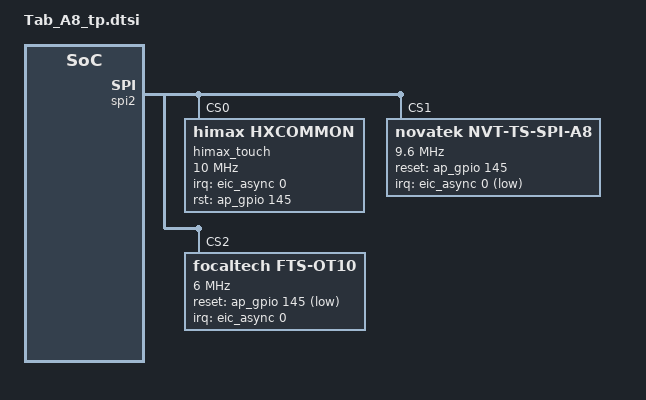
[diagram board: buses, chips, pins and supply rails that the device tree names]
/*Tab A8 code for SR-AX6300-01-23 by fengzhigang at 2021/08/04 start*/
/*Tab A8 code for SR-AX6300-01-373 by luxinjun at 2021/09/17 start*/
&spi2 {
	status = "okay";
	cs-gpios = <0>, <0>, <0>;

	himax_touch@0 {
		compatible = "himax,hxcommon";
		reg = <0>;
		status = "okay";
		spi-max-frequency = <10000000>;
		interrupt-parent = <&ap_gpio>;
		//interrupts = <144 0x2004>;
		himax,panel-sense-nums = <18 32>;
		himax,panel-coords = <0 1200 0 1920>;
		himax,display-coords = <0 1200 0 1920>;
		himax,panel-max-points = <10>;
		himax,int-is-edge = <1>;
		/*Tab A8 code for AX6300DEV-1776 by chenpengbo at 2021/10/28 start*/
		himax,irq-gpio = <&eic_async 0 GPIO_ACTIVE_HIGH>;
		/*Tab A8 code for AX6300DEV-1776 by chenpengbo at 2021/10/28 end*/
		himax,rst-gpio = <&ap_gpio 145 GPIO_ACTIVE_HIGH>;
		report_type = <1>;
	};

	/* Novatek device tree node */
	novatek@1 {
		compatible = "novatek,NVT-ts-spi-a8";
		reg = <1>; //Same as CS ID
		status = "ok";

		spi-max-frequency = <9600000>;	//4800000,9600000,15000000,19200000
		novatek,reset-gpio = <&ap_gpio 145 0x00>;
                /*Tab A8 code for AX6300DEV-1776 by chenpengbo at 2021/10/28 start*/
		novatek,irq-gpio = <&eic_async 0 0x2001>;
                /*Tab A8 code for AX6300DEV-1776 by chenpengbo at 2021/10/28 end*/

		//novatek,pen-support;
		//novatek,stylus-resol-double;

		/* 525 */
		//novatek,swrst-n8-addr = <0x01F01A>;

		/* 672A, 525B, 675, 526, 672C, 523 */
		novatek,swrst-n8-addr = <0x03F0FE>;
		novatek,spi-rd-fast-addr = <0x03F310>;
/*Tab A8 code for SR-AX6300-01-405 by luxinjun at 2021/09/09 start*/
				/*Panel setting*/
		novatek,resolution = <1200 1920>;
		novatek,max_touch_num = <10>;
		novatek,area-size = <56 112 60>;	//indicator navigation edge
		novatek,fw_name = "novatek_ts_fw.bin", "tsp_novatek/nt36525_a01core_tp.bin";
		novatek,fw_name_mp = "novatek_ts_mp.bin", "tsp_novatek/nt36525_a01core_mp.bin";
		//novatek,support_ear_detect_mode;
		novatek,enable_settings_aot;
/*Tab A8 code for SR-AX6300-01-405 by luxinjun at 2021/09/09 end*/
		/* MP */
		novatek,mp-support-dt;

		novatek-mp-criteria-723A@0 {
			#address-cells = <1>;
			#size-cells = <0>;
			compatible = "novatek-mp-criteria-723A";

			/* sec cmd test config */
			open_test_spec = <(-511) 5120>;
			short_test_spec = <10000 14008>;
			diff_test_frame = <50>;
			/* sec cmd fdm test config */
			fdm_x_num = <2>;
			fdm_diff_test_frame = <50>;

			/* MP Config */
			IC_X_CFG_SIZE = <32>;
			IC_Y_CFG_SIZE = <48>;
			IC_KEY_CFG_SIZE = <4>;
			X_Channel = <32>;
			Y_Channel = <48>;
			AIN_X = <0 1 2 3 4 5 6 7 8 9 10 11 12 13 14 15 16 17 18 19 20 21 22 23 24 25 26 27 28 29 30 31>;
			AIN_Y = <0 1 2 3 4 5 6 7 8 9 10 11 12 13 14 15 16 17
						18 19 20 21 22 23 24 25 26 27 28 29 30 31 32 33 34 35 36 37 38 39
						40 41 42 43 44 45 46 47>;
			AIN_KEY = <0 1 2 0xFF 0xFF 0xFF 0xFF 0xFF>;

			/* MP Criteria */
			PS_Config_Lmt_Short_Rawdata_P = <
				14008 14008 14008 14008 14008 14008 14008 14008 14008 14008 14008 14008 14008 14008 14008 14008 14008 14008 14008 14008 14008 14008 14008 14008 14008 14008 14008 14008 14008 14008 14008 14008
				14008 14008 14008 14008 14008 14008 14008 14008 14008 14008 14008 14008 14008 14008 14008 14008 14008 14008 14008 14008 14008 14008 14008 14008 14008 14008 14008 14008 14008 14008 14008 14008
				14008 14008 14008 14008 14008 14008 14008 14008 14008 14008 14008 14008 14008 14008 14008 14008 14008 14008 14008 14008 14008 14008 14008 14008 14008 14008 14008 14008 14008 14008 14008 14008
				14008 14008 14008 14008 14008 14008 14008 14008 14008 14008 14008 14008 14008 14008 14008 14008 14008 14008 14008 14008 14008 14008 14008 14008 14008 14008 14008 14008 14008 14008 14008 14008
				14008 14008 14008 14008 14008 14008 14008 14008 14008 14008 14008 14008 14008 14008 14008 14008 14008 14008 14008 14008 14008 14008 14008 14008 14008 14008 14008 14008 14008 14008 14008 14008
				14008 14008 14008 14008 14008 14008 14008 14008 14008 14008 14008 14008 14008 14008 14008 14008 14008 14008 14008 14008 14008 14008 14008 14008 14008 14008 14008 14008 14008 14008 14008 14008
				14008 14008 14008 14008 14008 14008 14008 14008 14008 14008 14008 14008 14008 14008 14008 14008 14008 14008 14008 14008 14008 14008 14008 14008 14008 14008 14008 14008 14008 14008 14008 14008
				14008 14008 14008 14008 14008 14008 14008 14008 14008 14008 14008 14008 14008 14008 14008 14008 14008 14008 14008 14008 14008 14008 14008 14008 14008 14008 14008 14008 14008 14008 14008 14008
				14008 14008 14008 14008 14008 14008 14008 14008 14008 14008 14008 14008 14008 14008 14008 14008 14008 14008 14008 14008 14008 14008 14008 14008 14008 14008 14008 14008 14008 14008 14008 14008
				14008 14008 14008 14008 14008 14008 14008 14008 14008 14008 14008 14008 14008 14008 14008 14008 14008 14008 14008 14008 14008 14008 14008 14008 14008 14008 14008 14008 14008 14008 14008 14008
				14008 14008 14008 14008 14008 14008 14008 14008 14008 14008 14008 14008 14008 14008 14008 14008 14008 14008 14008 14008 14008 14008 14008 14008 14008 14008 14008 14008 14008 14008 14008 14008
				14008 14008 14008 14008 14008 14008 14008 14008 14008 14008 14008 14008 14008 14008 14008 14008 14008 14008 14008 14008 14008 14008 14008 14008 14008 14008 14008 14008 14008 14008 14008 14008
				14008 14008 14008 14008 14008 14008 14008 14008 14008 14008 14008 14008 14008 14008 14008 14008 14008 14008 14008 14008 14008 14008 14008 14008 14008 14008 14008 14008 14008 14008 14008 14008
				14008 14008 14008 14008 14008 14008 14008 14008 14008 14008 14008 14008 14008 14008 14008 14008 14008 14008 14008 14008 14008 14008 14008 14008 14008 14008 14008 14008 14008 14008 14008 14008
				14008 14008 14008 14008 14008 14008 14008 14008 14008 14008 14008 14008 14008 14008 14008 14008 14008 14008 14008 14008 14008 14008 14008 14008 14008 14008 14008 14008 14008 14008 14008 14008
				14008 14008 14008 14008 14008 14008 14008 14008 14008 14008 14008 14008 14008 14008 14008 14008 14008 14008 14008 14008 14008 14008 14008 14008 14008 14008 14008 14008 14008 14008 14008 14008
				14008 14008 14008 14008 14008 14008 14008 14008 14008 14008 14008 14008 14008 14008 14008 14008 14008 14008 14008 14008 14008 14008 14008 14008 14008 14008 14008 14008 14008 14008 14008 14008
				14008 14008 14008 14008 14008 14008 14008 14008 14008 14008 14008 14008 14008 14008 14008 14008 14008 14008 14008 14008 14008 14008 14008 14008 14008 14008 14008 14008 14008 14008 14008 14008
				14008 14008 14008 14008 14008 14008 14008 14008 14008 14008 14008 14008 14008 14008 14008 14008 14008 14008 14008 14008 14008 14008 14008 14008 14008 14008 14008 14008 14008 14008 14008 14008
				14008 14008 14008 14008 14008 14008 14008 14008 14008 14008 14008 14008 14008 14008 14008 14008 14008 14008 14008 14008 14008 14008 14008 14008 14008 14008 14008 14008 14008 14008 14008 14008
				14008 14008 14008 14008 14008 14008 14008 14008 14008 14008 14008 14008 14008 14008 14008 14008 14008 14008 14008 14008 14008 14008 14008 14008 14008 14008 14008 14008 14008 14008 14008 14008
				14008 14008 14008 14008 14008 14008 14008 14008 14008 14008 14008 14008 14008 14008 14008 14008 14008 14008 14008 14008 14008 14008 14008 14008 14008 14008 14008 14008 14008 14008 14008 14008
				14008 14008 14008 14008 14008 14008 14008 14008 14008 14008 14008 14008 14008 14008 14008 14008 14008 14008 14008 14008 14008 14008 14008 14008 14008 14008 14008 14008 14008 14008 14008 14008
				14008 14008 14008 14008 14008 14008 14008 14008 14008 14008 14008 14008 14008 14008 14008 14008 14008 14008 14008 14008 14008 14008 14008 14008 14008 14008 14008 14008 14008 14008 14008 14008
				14008 14008 14008 14008 14008 14008 14008 14008 14008 14008 14008 14008 14008 14008 14008 14008 14008 14008 14008 14008 14008 14008 14008 14008 14008 14008 14008 14008 14008 14008 14008 14008
				14008 14008 14008 14008 14008 14008 14008 14008 14008 14008 14008 14008 14008 14008 14008 14008 14008 14008 14008 14008 14008 14008 14008 14008 14008 14008 14008 14008 14008 14008 14008 14008
				14008 14008 14008 14008 14008 14008 14008 14008 14008 14008 14008 14008 14008 14008 14008 14008 14008 14008 14008 14008 14008 14008 14008 14008 14008 14008 14008 14008 14008 14008 14008 14008
				14008 14008 14008 14008 14008 14008 14008 14008 14008 14008 14008 14008 14008 14008 14008 14008 14008 14008 14008 14008 14008 14008 14008 14008 14008 14008 14008 14008 14008 14008 14008 14008
				14008 14008 14008 14008 14008 14008 14008 14008 14008 14008 14008 14008 14008 14008 14008 14008 14008 14008 14008 14008 14008 14008 14008 14008 14008 14008 14008 14008 14008 14008 14008 14008
				14008 14008 14008 14008 14008 14008 14008 14008 14008 14008 14008 14008 14008 14008 14008 14008 14008 14008 14008 14008 14008 14008 14008 14008 14008 14008 14008 14008 14008 14008 14008 14008
				14008 14008 14008 14008 14008 14008 14008 14008 14008 14008 14008 14008 14008 14008 14008 14008 14008 14008 14008 14008 14008 14008 14008 14008 14008 14008 14008 14008 14008 14008 14008 14008
				14008 14008 14008 14008 14008 14008 14008 14008 14008 14008 14008 14008 14008 14008 14008 14008 14008 14008 14008 14008 14008 14008 14008 14008 14008 14008 14008 14008 14008 14008 14008 14008
				14008 14008 14008 14008 14008 14008 14008 14008 14008 14008 14008 14008 14008 14008 14008 14008 14008 14008 14008 14008 14008 14008 14008 14008 14008 14008 14008 14008 14008 14008 14008 14008
				14008 14008 14008 14008 14008 14008 14008 14008 14008 14008 14008 14008 14008 14008 14008 14008 14008 14008 14008 14008 14008 14008 14008 14008 14008 14008 14008 14008 14008 14008 14008 14008
				14008 14008 14008 14008 14008 14008 14008 14008 14008 14008 14008 14008 14008 14008 14008 14008 14008 14008 14008 14008 14008 14008 14008 14008 14008 14008 14008 14008 14008 14008 14008 14008
				14008 14008 14008 14008 14008 14008 14008 14008 14008 14008 14008 14008 14008 14008 14008 14008 14008 14008 14008 14008 14008 14008 14008 14008 14008 14008 14008 14008 14008 14008 14008 14008
				14008 14008 14008 14008 14008 14008 14008 14008 14008 14008 14008 14008 14008 14008 14008 14008 14008 14008 14008 14008 14008 14008 14008 14008 14008 14008 14008 14008 14008 14008 14008 14008
				14008 14008 14008 14008 14008 14008 14008 14008 14008 14008 14008 14008 14008 14008 14008 14008 14008 14008 14008 14008 14008 14008 14008 14008 14008 14008 14008 14008 14008 14008 14008 14008
				14008 14008 14008 14008 14008 14008 14008 14008 14008 14008 14008 14008 14008 14008 14008 14008 14008 14008 14008 14008 14008 14008 14008 14008 14008 14008 14008 14008 14008 14008 14008 14008
				14008 14008 14008 14008 14008 14008 14008 14008 14008 14008 14008 14008 14008 14008 14008 14008 14008 14008 14008 14008 14008 14008 14008 14008 14008 14008 14008 14008 14008 14008 14008 14008
				14008 14008 14008 14008 14008 14008 14008 14008 14008 14008 14008 14008 14008 14008 14008 14008 14008 14008 14008 14008 14008 14008 14008 14008 14008 14008 14008 14008 14008 14008 14008 14008
				14008 14008 14008 14008 14008 14008 14008 14008 14008 14008 14008 14008 14008 14008 14008 14008 14008 14008 14008 14008 14008 14008 14008 14008 14008 14008 14008 14008 14008 14008 14008 14008
				14008 14008 14008 14008 14008 14008 14008 14008 14008 14008 14008 14008 14008 14008 14008 14008 14008 14008 14008 14008 14008 14008 14008 14008 14008 14008 14008 14008 14008 14008 14008 14008
				14008 14008 14008 14008 14008 14008 14008 14008 14008 14008 14008 14008 14008 14008 14008 14008 14008 14008 14008 14008 14008 14008 14008 14008 14008 14008 14008 14008 14008 14008 14008 14008
				14008 14008 14008 14008 14008 14008 14008 14008 14008 14008 14008 14008 14008 14008 14008 14008 14008 14008 14008 14008 14008 14008 14008 14008 14008 14008 14008 14008 14008 14008 14008 14008
				14008 14008 14008 14008 14008 14008 14008 14008 14008 14008 14008 14008 14008 14008 14008 14008 14008 14008 14008 14008 14008 14008 14008 14008 14008 14008 14008 14008 14008 14008 14008 14008
				14008 14008 14008 14008 14008 14008 14008 14008 14008 14008 14008 14008 14008 14008 14008 14008 14008 14008 14008 14008 14008 14008 14008 14008 14008 14008 14008 14008 14008 14008 14008 14008
				14008 14008 14008 14008 14008 14008 14008 14008 14008 14008 14008 14008 14008 14008 14008 14008 14008 14008 14008 14008 14008 14008 14008 14008 14008 14008 14008 14008 14008 14008 14008 14008
				14008 14008 14008 14008 14008 14008 14008 14008 14008 14008 14008 14008 14008 14008 14008 14008 14008 14008 14008 14008 14008 14008 14008 14008 14008 14008 14008 14008 14008 14008 14008 14008
				14008 14008 14008 14008 14008 14008 14008 14008 14008 14008 14008 14008 14008 14008 14008 14008 14008 14008 14008 14008 14008 14008 14008 14008 14008 14008 14008 14008 14008 14008 14008 14008
				14008 14008 14008>;

			PS_Config_Lmt_Short_Rawdata_N = <
				10100	10100	10100	10100	10100	10100	10100	10100	10100	10100	10100	10100	10100	10100	10100	10100	10100	10100	10100	10100	10100	10100	10100	10100	10100	10100	10100	10100	10100	10100	10100	10100
				10100	10100	10100	10100	10100	10100	10100	10100	10100	10100	10100	10100	10100	10100	10100	10100	10100	10100	10100	10100	10100	10100	10100	10100	10100	10100	10100	10100	10100	10100	10100	10100
				10100	10100	10100	10100	10100	10100	10100	10100	10100	10100	10100	10100	10100	10100	10100	10100	10100	10100	10100	10100	10100	10100	10100	10100	10100	10100	10100	10100	10100	10100	10100	10100
				10100	10100	10100	10100	10100	10100	10100	10100	10100	10100	10100	10100	10100	10100	10100	10100	10100	10100	10100	10100	10100	10100	10100	10100	10100	10100	10100	10100	10100	10100	10100	10100
				10100	10100	10100	10100	10100	10100	10100	10100	10100	10100	10100	10100	10100	10100	10100	10100	10100	10100	10100	10100	10100	10100	10100	10100	10100	10100	10100	10100	10100	10100	10100	10100
				10100	10100	10100	10100	10100	10100	10100	10100	10100	10100	10100	10100	10100	10100	10100	10100	10100	10100	10100	10100	10100	10100	10100	10100	10100	10100	10100	10100	10100	10100	10100	10100
				10100	10100	10100	10100	10100	10100	10100	10100	10100	10100	10100	10100	10100	10100	10100	10100	10100	10100	10100	10100	10100	10100	10100	10100	10100	10100	10100	10100	10100	10100	10100	10100
				10100	10100	10100	10100	10100	10100	10100	10100	10100	10100	10100	10100	10100	10100	10100	10100	10100	10100	10100	10100	10100	10100	10100	10100	10100	10100	10100	10100	10100	10100	10100	10100
				10100	10100	10100	10100	10100	10100	10100	10100	10100	10100	10100	10100	10100	10100	10100	10100	10100	10100	10100	10100	10100	10100	10100	10100	10100	10100	10100	10100	10100	10100	10100	10100
				10100	10100	10100	10100	10100	10100	10100	10100	10100	10100	10100	10100	10100	10100	10100	10100	10100	10100	10100	10100	10100	10100	10100	10100	10100	10100	10100	10100	10100	10100	10100	10100
				10100	10100	10100	10100	10100	10100	10100	10100	10100	10100	10100	10100	10100	10100	10100	10100	10100	10100	10100	10100	10100	10100	10100	10100	10100	10100	10100	10100	10100	10100	10100	10100
				10100	10100	10100	10100	10100	10100	10100	10100	10100	10100	10100	10100	10100	10100	10100	10100	10100	10100	10100	10100	10100	10100	10100	10100	10100	10100	10100	10100	10100	10100	10100	10100
				10100	10100	10100	10100	10100	10100	10100	10100	10100	10100	10100	10100	10100	10100	10100	10100	10100	10100	10100	10100	10100	10100	10100	10100	10100	10100	10100	10100	10100	10100	10100	10100
				10100	10100	10100	10100	10100	10100	10100	10100	10100	10100	10100	10100	10100	10100	10100	10100	10100	10100	10100	10100	10100	10100	10100	10100	10100	10100	10100	10100	10100	10100	10100	10100
				10100	10100	10100	10100	10100	10100	10100	10100	10100	10100	10100	10100	10100	10100	10100	10100	10100	10100	10100	10100	10100	10100	10100	10100	10100	10100	10100	10100	10100	10100	10100	10100
				10100	10100	10100	10100	10100	10100	10100	10100	10100	10100	10100	10100	10100	10100	10100	10100	10100	10100	10100	10100	10100	10100	10100	10100	10100	10100	10100	10100	10100	10100	10100	10100
				10100	10100	10100	10100	10100	10100	10100	10100	10100	10100	10100	10100	10100	10100	10100	10100	10100	10100	10100	10100	10100	10100	10100	10100	10100	10100	10100	10100	10100	10100	10100	10100
				10100	10100	10100	10100	10100	10100	10100	10100	10100	10100	10100	10100	10100	10100	10100	10100	10100	10100	10100	10100	10100	10100	10100	10100	10100	10100	10100	10100	10100	10100	10100	10100
				10100	10100	10100	10100	10100	10100	10100	10100	10100	10100	10100	10100	10100	10100	10100	10100	10100	10100	10100	10100	10100	10100	10100	10100	10100	10100	10100	10100	10100	10100	10100	10100
				10100	10100	10100	10100	10100	10100	10100	10100	10100	10100	10100	10100	10100	10100	10100	10100	10100	10100	10100	10100	10100	10100	10100	10100	10100	10100	10100	10100	10100	10100	10100	10100
				10100	10100	10100	10100	10100	10100	10100	10100	10100	10100	10100	10100	10100	10100	10100	10100	10100	10100	10100	10100	10100	10100	10100	10100	10100	10100	10100	10100	10100	10100	10100	10100
				10100	10100	10100	10100	10100	10100	10100	10100	10100	10100	10100	10100	10100	10100	10100	10100	10100	10100	10100	10100	10100	10100	10100	10100	10100	10100	10100	10100	10100	10100	10100	10100
				10100	10100	10100	10100	10100	10100	10100	10100	10100	10100	10100	10100	10100	10100	10100	10100	10100	10100	10100	10100	10100	10100	10100	10100	10100	10100	10100	10100	10100	10100	10100	10100
				10100	10100	10100	10100	10100	10100	10100	10100	10100	10100	10100	10100	10100	10100	10100	10100	10100	10100	10100	10100	10100	10100	10100	10100	10100	10100	10100	10100	10100	10100	10100	10100
				10100	10100	10100	10100	10100	10100	10100	10100	10100	10100	10100	10100	10100	10100	10100	10100	10100	10100	10100	10100	10100	10100	10100	10100	10100	10100	10100	10100	10100	10100	10100	10100
				10100	10100	10100	10100	10100	10100	10100	10100	10100	10100	10100	10100	10100	10100	10100	10100	10100	10100	10100	10100	10100	10100	10100	10100	10100	10100	10100	10100	10100	10100	10100	10100
				10100	10100	10100	10100	10100	10100	10100	10100	10100	10100	10100	10100	10100	10100	10100	10100	10100	10100	10100	10100	10100	10100	10100	10100	10100	10100	10100	10100	10100	10100	10100	10100
				10100	10100	10100	10100	10100	10100	10100	10100	10100	10100	10100	10100	10100	10100	10100	10100	10100	10100	10100	10100	10100	10100	10100	10100	10100	10100	10100	10100	10100	10100	10100	10100
				10100	10100	10100	10100	10100	10100	10100	10100	10100	10100	10100	10100	10100	10100	10100	10100	10100	10100	10100	10100	10100	10100	10100	10100	10100	10100	10100	10100	10100	10100	10100	10100
				10100	10100	10100	10100	10100	10100	10100	10100	10100	10100	10100	10100	10100	10100	10100	10100	10100	10100	10100	10100	10100	10100	10100	10100	10100	10100	10100	10100	10100	10100	10100	10100
				10100	10100	10100	10100	10100	10100	10100	10100	10100	10100	10100	10100	10100	10100	10100	10100	10100	10100	10100	10100	10100	10100	10100	10100	10100	10100	10100	10100	10100	10100	10100	10100
				10100	10100	10100	10100	10100	10100	10100	10100	10100	10100	10100	10100	10100	10100	10100	10100	10100	10100	10100	10100	10100	10100	10100	10100	10100	10100	10100	10100	10100	10100	10100	10100
				10100	10100	10100	10100	10100	10100	10100	10100	10100	10100	10100	10100	10100	10100	10100	10100	10100	10100	10100	10100	10100	10100	10100	10100	10100	10100	10100	10100	10100	10100	10100	10100
				10100	10100	10100	10100	10100	10100	10100	10100	10100	10100	10100	10100	10100	10100	10100	10100	10100	10100	10100	10100	10100	10100	10100	10100	10100	10100	10100	10100	10100	10100	10100	10100
				10100	10100	10100	10100	10100	10100	10100	10100	10100	10100	10100	10100	10100	10100	10100	10100	10100	10100	10100	10100	10100	10100	10100	10100	10100	10100	10100	10100	10100	10100	10100	10100
				10100	10100	10100	10100	10100	10100	10100	10100	10100	10100	10100	10100	10100	10100	10100	10100	10100	10100	10100	10100	10100	10100	10100	10100	10100	10100	10100	10100	10100	10100	10100	10100
				10100	10100	10100	10100	10100	10100	10100	10100	10100	10100	10100	10100	10100	10100	10100	10100	10100	10100	10100	10100	10100	10100	10100	10100	10100	10100	10100	10100	10100	10100	10100	10100
				10100	10100	10100	10100	10100	10100	10100	10100	10100	10100	10100	10100	10100	10100	10100	10100	10100	10100	10100	10100	10100	10100	10100	10100	10100	10100	10100	10100	10100	10100	10100	10100
				10100	10100	10100	10100	10100	10100	10100	10100	10100	10100	10100	10100	10100	10100	10100	10100	10100	10100	10100	10100	10100	10100	10100	10100	10100	10100	10100	10100	10100	10100	10100	10100
				10100	10100	10100	10100	10100	10100	10100	10100	10100	10100	10100	10100	10100	10100	10100	10100	10100	10100	10100	10100	10100	10100	10100	10100	10100	10100	10100	10100	10100	10100	10100	10100
				10100	10100	10100	10100	10100	10100	10100	10100	10100	10100	10100	10100	10100	10100	10100	10100	10100	10100	10100	10100	10100	10100	10100	10100	10100	10100	10100	10100	10100	10100	10100	10100
				10100	10100	10100	10100	10100	10100	10100	10100	10100	10100	10100	10100	10100	10100	10100	10100	10100	10100	10100	10100	10100	10100	10100	10100	10100	10100	10100	10100	10100	10100	10100	10100
				10100	10100	10100	10100	10100	10100	10100	10100	10100	10100	10100	10100	10100	10100	10100	10100	10100	10100	10100	10100	10100	10100	10100	10100	10100	10100	10100	10100	10100	10100	10100	10100
				10100	10100	10100	10100	10100	10100	10100	10100	10100	10100	10100	10100	10100	10100	10100	10100	10100	10100	10100	10100	10100	10100	10100	10100	10100	10100	10100	10100	10100	10100	10100	10100
				10100	10100	10100	10100	10100	10100	10100	10100	10100	10100	10100	10100	10100	10100	10100	10100	10100	10100	10100	10100	10100	10100	10100	10100	10100	10100	10100	10100	10100	10100	10100	10100
				10100	10100	10100	10100	10100	10100	10100	10100	10100	10100	10100	10100	10100	10100	10100	10100	10100	10100	10100	10100	10100	10100	10100	10100	10100	10100	10100	10100	10100	10100	10100	10100
				10100	10100	10100	10100	10100	10100	10100	10100	10100	10100	10100	10100	10100	10100	10100	10100	10100	10100	10100	10100	10100	10100	10100	10100	10100	10100	10100	10100	10100	10100	10100	10100
				10100	10100	10100	10100	10100	10100	10100	10100	10100	10100	10100	10100	10100	10100	10100	10100	10100	10100	10100	10100	10100	10100	10100	10100	10100	10100	10100	10100	10100	10100	10100	10100
				10000 10000 10000>;

			PS_Config_Lmt_Open_Rawdata_P = <
				3630	3607	3327	3256	3334	3276	3203	3162	3406	3257	3304	3343	3444	3467	3526	3494	3858	3803	3515	3444	3385	3347	3288	3246	3570	3449	3532	3582	3505	3570	3649	3551
				3743	3630	3346	3264	3313	3242	3224	3169	3381	3239	3318	3362	3427	3493	3490	3467	3887	3789	3525	3452	3375	3318	3281	3242	3542	3451	3536	3606	3540	3592	3586	3605
				3683	3416	3290	3214	3294	3257	3187	3116	3407	3227	3277	3326	3367	3453	3470	3493	3826	3600	3493	3397	3340	3306	3269	3201	3589	3424	3479	3564	3463	3528	3577	3628
				3690	3463	3308	3243	3316	3245	3157	3144	3334	3217	3273	3348	3399	3456	3507	3467	3845	3633	3500	3421	3365	3304	3241	3201	3521	3402	3491	3584	3502	3572	3616	3578
				3721	3423	3365	3182	3259	3220	3171	3103	3320	3213	3262	3313	3371	3402	3466	3448	3868	3586	3547	3388	3305	3266	3234	3185	3483	3442	3467	3526	3460	3502	3553	3568
				3617	3407	3409	3204	3294	3243	3168	3078	3382	3176	3253	3311	3397	3434	3477	3486	3815	3596	3582	3383	3339	3294	3239	3157	3553	3400	3452	3547	3490	3546	3600	3613
				3669	3424	3371	3320	3228	3189	3138	3089	3308	3150	3252	3304	3361	3411	3417	3449	3827	3610	3536	3498	3304	3234	3200	3152	3473	3365	3494	3525	3435	3504	3530	3551
				3638	3367	3362	3357	3249	3221	3162	3094	3358	3189	3214	3295	3351	3435	3459	3458	3785	3574	3550	3533	3294	3269	3227	3159	3512	3403	3451	3501	3453	3535	3579	3600
				3619	3396	3371	3319	3393	3166	3115	3063	3280	3140	3176	3287	3341	3403	3425	3385	3763	3578	3557	3488	3431	3242	3173	3127	3455	3347	3402	3539	3424	3484	3526	3522
				3631	3367	3315	3316	3425	3186	3148	3082	3305	3159	3214	3252	3334	3396	3453	3430	3770	3547	3523	3498	3462	3227	3214	3150	3483	3354	3446	3498	3406	3505	3560	3572
				3572	3357	3347	3329	3379	3315	3092	3029	3266	3110	3171	3220	3337	3400	3420	3407	3740	3518	3526	3509	3418	3353	3179	3088	3420	3330	3392	3459	3452	3486	3512	3526
				3647	3351	3322	3259	3375	3343	3108	3061	3273	3122	3199	3259	3304	3386	3411	3435	3792	3514	3504	3465	3421	3381	3164	3127	3452	3337	3406	3502	3409	3462	3530	3558
				3585	3323	3315	3292	3382	3299	3243	3011	3283	3103	3150	3218	3266	3395	3421	3404	3711	3514	3476	3467	3428	3346	3294	3096	3445	3292	3382	3452	3376	3515	3518	3518
				3640	3374	3306	3269	3323	3304	3259	3031	3232	3122	3168	3248	3306	3368	3416	3395	3780	3540	3469	3445	3395	3354	3316	3085	3441	3326	3400	3470	3425	3477	3507	3536
				3571	3336	3276	3255	3353	3306	3215	3095	3206	3115	3147	3197	3264	3330	3416	3393	3711	3481	3466	3413	3392	3360	3277	3150	3393	3309	3351	3441	3376	3448	3547	3512
				3606	3362	3322	3238	3318	3242	3215	3108	3285	3068	3158	3208	3292	3369	3385	3383	3774	3522	3490	3399	3364	3316	3278	3169	3444	3292	3379	3451	3383	3491	3504	3495
				3560	3304	3285	3207	3302	3271	3215	3067	3214	3040	3147	3186	3241	3325	3351	3393	3698	3465	3431	3395	3332	3312	3284	3134	3368	3266	3357	3399	3353	3442	3476	3544
				3593	3337	3320	3253	3291	3243	3158	3073	3242	3103	3102	3199	3249	3355	3392	3365	3703	3526	3479	3414	3323	3290	3245	3137	3431	3284	3343	3432	3367	3453	3525	3500
				3557	3298	3255	3211	3257	3224	3187	3071	3189	3049	3070	3194	3234	3301	3353	3333	3718	3455	3411	3351	3316	3255	3242	3141	3400	3241	3316	3416	3325	3420	3481	3473
				3530	3325	3285	3243	3301	3211	3158	3017	3228	3063	3148	3150	3248	3308	3389	3369	3662	3463	3477	3393	3334	3249	3217	3102	3381	3284	3344	3397	3355	3431	3493	3521
				3539	3292	3245	3175	3255	3178	3137	3040	3148	3038	3092	3119	3236	3281	3336	3327	3684	3470	3404	3326	3273	3236	3180	3095	3368	3248	3297	3371	3333	3379	3459	3472
				3529	3263	3274	3203	3291	3221	3126	3014	3201	3046	3102	3193	3194	3315	3348	3367	3663	3411	3417	3389	3315	3257	3179	3073	3372	3232	3340	3399	3320	3421	3473	3486
				3522	3277	3236	3161	3224	3182	3096	2997	3159	2994	3078	3140	3168	3306	3330	3318	3637	3434	3417	3316	3253	3204	3169	3043	3368	3210	3305	3351	3294	3402	3434	3458
				3549	3255	3215	3189	3252	3214	3143	2983	3141	3026	3084	3145	3241	3260	3351	3327	3684	3417	3364	3325	3312	3243	3190	3039	3333	3215	3288	3390	3320	3388	3463	3466
				3480	3257	3225	3143	3208	3151	3101	2952	3190	3003	3036	3129	3190	3231	3369	3319	3633	3402	3382	3318	3241	3183	3138	3028	3358	3213	3273	3360	3283	3355	3469	3439
				3551	3274	3189	3122	3236	3173	3131	2998	3134	2980	3067	3130	3196	3305	3325	3336	3704	3418	3357	3267	3252	3239	3178	3046	3312	3185	3276	3347	3322	3386	3456	3463
				3483	3229	3187	3133	3187	3137	3074	2958	3186	3021	3050	3075	3171	3243	3304	3346	3648	3397	3337	3285	3248	3168	3120	2997	3381	3201	3276	3322	3283	3340	3427	3458
				3483	3255	3203	3096	3157	3151	3087	2977	3115	2970	3017	3106	3172	3259	3375	3301	3612	3431	3353	3259	3187	3171	3166	3025	3306	3164	3242	3326	3273	3388	3460	3446
				3508	3210	3154	3092	3164	3099	3049	2919	3106	2997	3059	3087	3117	3234	3312	3287	3662	3396	3323	3235	3200	3161	3092	2968	3291	3200	3256	3329	3249	3347	3413	3425
				3463	3217	3182	3102	3131	3075	3070	2934	3150	2931	3004	3052	3144	3231	3316	3355	3621	3365	3358	3248	3179	3109	3101	3018	3330	3150	3215	3291	3249	3334	3452	3455
				3469	3213	3113	3053	3126	3081	3018	2896	3085	2945	3029	3094	3126	3172	3298	3305	3606	3385	3295	3220	3155	3123	3089	2947	3284	3136	3253	3302	3253	3312	3417	3416
				3458	3186	3117	3085	3140	3052	2994	2916	3106	2952	2968	3050	3096	3204	3298	3313	3631	3353	3266	3252	3169	3101	3040	2959	3299	3152	3207	3271	3227	3313	3404	3466
				3439	3185	3112	3029	3089	3046	3001	2864	3084	2919	2987	3075	3138	3186	3241	3291	3593	3341	3277	3201	3138	3081	3057	2951	3253	3129	3199	3312	3239	3318	3386	3425
				3476	3164	3082	3022	3109	3047	2963	2829	3073	2914	2996	3012	3088	3148	3269	3292	3617	3341	3249	3164	3159	3082	3021	2892	3267	3122	3215	3263	3201	3280	3383	3411
				3428	3144	3078	3012	3050	2997	2956	2836	3049	2899	2954	3021	3112	3194	3246	3235	3563	3322	3236	3173	3108	3053	3003	2906	3253	3091	3183	3242	3235	3298	3385	3392
				3465	3151	3061	2986	3049	3028	2968	2809	3031	2885	2949	3031	3053	3145	3213	3266	3596	3322	3238	3147	3085	3080	3012	2882	3245	3102	3175	3260	3199	3262	3347	3393
				3388	3130	3042	2980	3040	2968	2919	2801	2975	2870	2942	2997	3064	3172	3255	3250	3554	3270	3218	3134	3094	3029	2982	2868	3179	3082	3152	3235	3179	3298	3362	3396
				3430	3159	3050	2965	3012	2969	2952	2809	2951	2863	2930	2993	3077	3108	3213	3221	3586	3311	3220	3134	3067	3010	3011	2879	3169	3075	3165	3229	3200	3252	3330	3360
				3382	3106	3033	2951	3008	2962	2893	2765	2975	3025	2913	2982	3039	3123	3239	3271	3542	3271	3171	3122	3054	3017	2956	2847	3172	3236	3144	3204	3171	3239	3368	3389
				3410	3115	3053	2961	2991	2933	2893	2795	2948	3007	2903	2976	3042	3140	3173	3229	3554	3287	3199	3122	3054	2989	2940	2875	3158	3228	3134	3220	3173	3263	3323	3354
				3358	3068	3010	2944	2976	2927	2885	2737	2916	3036	3063	2959	3029	3101	3186	3260	3543	3250	3171	3071	3038	2976	2945	2825	3133	3235	3291	3199	3145	3235	3308	3403
				3355	3089	3015	2961	2977	2906	2856	2734	2941	3004	3039	2945	3018	3098	3201	3196	3515	3249	3185	3098	3036	2973	2916	2811	3158	3220	3277	3187	3158	3231	3330	3360
				3372	3050	2972	2909	2962	2893	2850	2727	2913	2970	3070	3094	3001	3084	3165	3220	3521	3239	3151	3064	2990	2956	2905	2818	3087	3193	3288	3329	3137	3203	3304	3355
				3385	3033	2990	2923	2991	2905	2840	2709	2913	2993	3035	3070	2989	3080	3166	3243	3512	3201	3148	3085	3024	2966	2912	2800	3133	3217	3267	3313	3131	3221	3301	3381
				3361	3053	2954	2882	2937	2892	2828	2702	2864	2968	3000	3105	3094	3066	3151	3200	3491	3210	3138	3053	2993	2920	2895	2786	3075	3145	3238	3330	3229	3203	3274	3351
				3382	3046	2941	2900	2940	2907	2828	2683	2891	2963	3031	3074	3078	3049	3143	3197	3522	3206	3102	3053	3000	2944	2893	2780	3119	3186	3274	3313	3220	3196	3288	3350
				3313	3025	2951	2865	2902	2857	2818	2674	2858	2919	3007	3040	3103	3112	3133	3185	3460	3180	3102	3042	2972	2917	2847	2765	3063	3133	3204	3285	3229	3259	3274	3323
				3361	3050	2962	2864	2927	2867	2840	2683	2892	2955	3015	3084	3087	3108	3122	3194	3504	3207	3116	3015	2980	2931	2879	2770	3091	3187	3257	3340	3225	3264	3280	3318
				5120 5120 5120>;

			PS_Config_Lmt_Open_Rawdata_N = <
				1555	1546	1426	1395	1429	1404	1372	1355	1459	1396	1416	1432	1476	1486	1511	1497	1653	1630	1506	1476	1450	1434	1409	1391	1530	1478	1513	1535	1502	1530	1564	1522
				1604	1555	1434	1399	1420	1389	1381	1358	1449	1388	1422	1441	1468	1497	1495	1486	1666	1624	1510	1479	1446	1422	1406	1389	1518	1479	1515	1545	1517	1539	1537	1545
				1578	1464	1410	1377	1411	1396	1366	1335	1460	1383	1404	1425	1443	1480	1487	1497	1639	1543	1497	1456	1431	1417	1401	1372	1538	1467	1491	1527	1484	1512	1533	1555
				1581	1484	1417	1390	1421	1390	1353	1347	1429	1378	1402	1435	1456	1481	1503	1486	1648	1557	1500	1466	1442	1416	1389	1372	1509	1458	1496	1536	1501	1531	1549	1533
				1594	1467	1442	1363	1396	1380	1359	1330	1423	1377	1398	1420	1444	1458	1485	1477	1657	1537	1520	1452	1416	1399	1386	1365	1492	1475	1486	1511	1483	1501	1522	1529
				1550	1460	1461	1373	1411	1390	1357	1319	1449	1361	1394	1419	1456	1471	1490	1494	1635	1541	1535	1450	1431	1411	1388	1353	1522	1457	1479	1520	1495	1519	1543	1548
				1572	1467	1444	1423	1383	1366	1345	1324	1417	1350	1393	1416	1440	1462	1464	1478	1640	1547	1515	1499	1416	1386	1371	1351	1488	1442	1497	1510	1472	1501	1513	1522
				1559	1443	1441	1438	1392	1380	1355	1326	1439	1366	1377	1412	1436	1472	1482	1482	1622	1531	1521	1514	1411	1401	1383	1354	1505	1458	1479	1500	1480	1515	1534	1543
				1551	1455	1444	1422	1454	1357	1335	1312	1405	1345	1361	1408	1432	1458	1468	1450	1612	1533	1524	1495	1470	1389	1360	1340	1480	1434	1458	1516	1467	1493	1511	1509
				1556	1443	1420	1421	1468	1365	1349	1321	1416	1354	1377	1393	1429	1455	1480	1470	1615	1520	1510	1499	1483	1383	1377	1350	1492	1437	1477	1499	1459	1502	1525	1531
				1531	1438	1434	1426	1448	1420	1325	1298	1399	1333	1359	1380	1430	1457	1465	1460	1603	1507	1511	1504	1465	1437	1362	1323	1465	1427	1453	1482	1479	1494	1505	1511
				1563	1436	1423	1396	1446	1432	1332	1312	1402	1338	1371	1396	1416	1451	1462	1472	1625	1506	1501	1485	1466	1449	1356	1340	1479	1430	1459	1501	1461	1483	1513	1525
				1536	1424	1420	1411	1449	1414	1390	1290	1407	1330	1350	1379	1399	1455	1466	1459	1590	1506	1489	1486	1469	1434	1411	1327	1476	1411	1449	1479	1447	1506	1507	1507
				1560	1446	1417	1401	1424	1416	1396	1299	1385	1338	1357	1392	1417	1443	1464	1455	1620	1517	1486	1476	1455	1437	1421	1322	1474	1425	1457	1487	1468	1490	1503	1515
				1530	1429	1404	1395	1437	1417	1378	1326	1374	1335	1348	1370	1399	1427	1464	1454	1590	1492	1485	1462	1453	1440	1404	1350	1454	1418	1436	1474	1447	1477	1520	1505
				1545	1441	1423	1387	1422	1389	1378	1332	1408	1315	1353	1375	1411	1444	1450	1450	1617	1509	1495	1456	1441	1421	1405	1358	1476	1411	1448	1479	1450	1496	1501	1498
				1525	1416	1408	1374	1415	1402	1378	1314	1377	1303	1348	1365	1389	1425	1436	1454	1585	1485	1470	1455	1428	1419	1407	1343	1443	1399	1438	1456	1437	1475	1489	1519
				1540	1430	1423	1394	1410	1390	1353	1317	1389	1330	1329	1371	1392	1438	1453	1442	1587	1511	1491	1463	1424	1410	1390	1344	1470	1407	1432	1471	1443	1480	1510	1500
				1524	1413	1395	1376	1396	1381	1366	1316	1366	1306	1315	1369	1386	1414	1437	1428	1593	1480	1462	1436	1421	1395	1389	1346	1457	1389	1421	1464	1425	1465	1492	1488
				1513	1425	1408	1390	1414	1376	1353	1293	1383	1312	1349	1350	1392	1417	1452	1444	1569	1484	1490	1454	1429	1392	1378	1329	1449	1407	1433	1456	1438	1470	1497	1509
				1516	1411	1390	1360	1395	1362	1344	1303	1349	1302	1325	1336	1387	1406	1429	1426	1579	1487	1459	1425	1402	1387	1363	1326	1443	1392	1413	1444	1428	1448	1482	1488
				1512	1398	1403	1372	1410	1380	1339	1291	1372	1305	1329	1368	1369	1420	1435	1443	1570	1462	1464	1452	1420	1396	1362	1317	1445	1385	1431	1456	1423	1466	1488	1494
				1509	1404	1387	1354	1381	1363	1327	1284	1354	1283	1319	1345	1357	1417	1427	1422	1558	1471	1464	1421	1394	1373	1358	1304	1443	1375	1416	1436	1411	1458	1471	1482
				1521	1395	1378	1366	1393	1377	1347	1278	1346	1297	1321	1348	1389	1397	1436	1426	1579	1464	1441	1425	1419	1390	1367	1302	1428	1378	1409	1453	1423	1452	1484	1485
				1491	1396	1382	1347	1375	1350	1329	1265	1367	1287	1301	1341	1367	1384	1444	1422	1557	1458	1449	1422	1389	1364	1345	1297	1439	1377	1402	1440	1407	1438	1486	1474
				1522	1403	1366	1338	1387	1360	1342	1285	1343	1277	1314	1341	1369	1416	1425	1429	1587	1465	1438	1400	1393	1388	1362	1305	1419	1365	1404	1434	1423	1451	1481	1484
				1492	1384	1366	1342	1366	1344	1317	1267	1365	1294	1307	1318	1359	1390	1416	1434	1563	1456	1430	1408	1392	1357	1337	1284	1449	1372	1404	1423	1407	1431	1468	1482
				1492	1395	1372	1327	1353	1350	1323	1276	1335	1273	1293	1331	1359	1396	1446	1414	1548	1470	1437	1396	1366	1359	1357	1296	1417	1356	1389	1425	1402	1452	1483	1477
				1503	1375	1351	1325	1356	1328	1306	1251	1331	1284	1311	1323	1336	1386	1419	1408	1569	1455	1424	1386	1371	1354	1325	1272	1410	1371	1395	1426	1392	1434	1462	1468
				1484	1378	1363	1329	1342	1318	1315	1257	1350	1256	1287	1308	1347	1384	1421	1438	1552	1442	1439	1392	1362	1332	1329	1293	1427	1350	1378	1410	1392	1429	1479	1480
				1486	1377	1334	1308	1339	1320	1293	1241	1322	1262	1298	1326	1339	1359	1413	1416	1545	1450	1412	1380	1352	1338	1324	1263	1407	1344	1394	1415	1394	1419	1464	1464
				1482	1365	1336	1322	1345	1308	1283	1249	1331	1265	1272	1307	1327	1373	1413	1420	1556	1437	1399	1393	1358	1329	1303	1268	1414	1351	1374	1402	1383	1420	1459	1485
				1474	1365	1333	1298	1324	1305	1286	1227	1321	1251	1280	1318	1345	1365	1389	1410	1540	1432	1404	1372	1345	1320	1310	1264	1394	1341	1371	1419	1388	1422	1451	1468
				1489	1356	1321	1295	1332	1306	1270	1212	1317	1249	1284	1291	1323	1349	1401	1411	1550	1432	1392	1356	1354	1321	1294	1239	1400	1338	1378	1398	1372	1405	1450	1462
				1469	1347	1319	1291	1307	1284	1267	1215	1306	1242	1266	1294	1333	1369	1391	1386	1527	1423	1387	1360	1332	1308	1287	1245	1394	1324	1364	1389	1386	1413	1450	1453
				1485	1350	1312	1279	1306	1297	1272	1204	1299	1236	1264	1299	1308	1348	1377	1399	1541	1423	1387	1348	1322	1320	1291	1235	1390	1329	1360	1397	1371	1398	1434	1454
				1452	1341	1303	1277	1303	1272	1251	1200	1275	1230	1261	1284	1313	1359	1395	1393	1523	1401	1379	1343	1326	1298	1278	1229	1362	1321	1351	1386	1362	1413	1441	1455
				1470	1354	1307	1270	1291	1272	1265	1204	1264	1227	1255	1282	1318	1332	1377	1380	1537	1419	1380	1343	1314	1290	1290	1234	1358	1318	1356	1384	1371	1393	1427	1440
				1449	1331	1300	1264	1289	1269	1240	1185	1275	1296	1248	1278	1302	1338	1388	1402	1518	1402	1359	1338	1309	1293	1267	1220	1359	1387	1347	1373	1359	1388	1443	1452
				1461	1335	1308	1269	1282	1257	1240	1198	1263	1288	1244	1275	1303	1345	1360	1384	1523	1408	1371	1338	1309	1281	1260	1232	1353	1383	1343	1380	1360	1398	1424	1437
				1439	1315	1290	1261	1275	1254	1236	1173	1249	1301	1312	1268	1298	1329	1365	1397	1518	1393	1359	1316	1302	1275	1262	1210	1342	1386	1410	1371	1348	1386	1417	1458
				1438	1324	1292	1269	1276	1245	1224	1171	1260	1287	1302	1262	1293	1327	1372	1369	1506	1392	1365	1327	1301	1274	1249	1204	1353	1380	1404	1366	1353	1384	1427	1440
				1445	1307	1273	1246	1269	1240	1221	1168	1248	1273	1315	1326	1286	1321	1356	1380	1509	1388	1350	1313	1281	1267	1245	1207	1323	1368	1409	1426	1344	1372	1416	1438
				1450	1300	1281	1252	1282	1245	1217	1161	1248	1282	1300	1315	1281	1320	1357	1390	1505	1372	1349	1322	1296	1271	1248	1200	1342	1378	1400	1420	1342	1380	1414	1449
				1440	1308	1266	1235	1258	1239	1212	1158	1227	1272	1285	1330	1326	1314	1350	1371	1496	1375	1345	1308	1282	1251	1240	1194	1318	1348	1387	1427	1384	1372	1403	1436
				1449	1305	1260	1243	1260	1246	1212	1150	1239	1270	1299	1317	1319	1306	1347	1370	1509	1374	1329	1308	1285	1261	1240	1191	1336	1365	1403	1420	1380	1369	1409	1435
				1420	1296	1264	1228	1243	1224	1207	1146	1225	1251	1288	1303	1330	1333	1342	1365	1483	1363	1329	1303	1273	1250	1220	1185	1312	1342	1373	1408	1384	1396	1403	1424
				1440	1307	1269	1227	1254	1228	1217	1150	1239	1266	1292	1321	1323	1332	1338	1369	1501	1374	1335	1292	1277	1256	1234	1187	1324	1366	1396	1431	1382	1399	1405	1422
				(-511) (-511) (-511)>;

			PS_Config_Lmt_FW_Rawdata_P = <
				1113	1118	1141	1131	1131	1118	1124	1121	1118	1121	1125	1125	1121	1122	1107	1113	1114	1118	1124	1120	1117	1104	1115	1128	1107	1122	1122	1132	1114	1118	1128	1117
				1103	1127	1124	1127	1128	1122	1115	1122	1125	1135	1121	1114	1108	1118	1121	1128	1124	1128	1121	1132	1111	1101	1115	1124	1110	1120	1124	1118	1125	1134	1124	1121
				1101	1115	1121	1139	1125	1124	1120	1120	1124	1125	1128	1118	1117	1124	1115	1114	1122	1138	1128	1122	1111	1122	1113	1115	1110	1110	1127	1122	1127	1118	1128	1121
				1120	1125	1127	1122	1132	1125	1121	1122	1117	1121	1125	1104	1121	1122	1120	1124	1117	1122	1118	1124	1125	1113	1120	1125	1118	1114	1118	1114	1120	1131	1132	1114
				1117	1121	1120	1121	1118	1129	1122	1117	1117	1115	1127	1120	1132	1127	1124	1125	1125	1117	1104	1124	1125	1120	1118	1110	1122	1111	1106	1129	1121	1128	1121	1120
				1129	1113	1124	1131	1118	1125	1120	1121	1118	1127	1122	1101	1115	1125	1134	1118	1120	1120	1122	1110	1121	1115	1121	1135	1110	1118	1117	1120	1113	1124	1125	1104
				1118	1125	1121	1121	1118	1107	1131	1127	1115	1118	1111	1128	1113	1138	1125	1113	1118	1120	1122	1100	1114	1124	1128	1118	1115	1124	1110	1103	1127	1124	1122	1125
				1131	1114	1117	1122	1129	1117	1122	1111	1117	1121	1122	1124	1106	1121	1125	1122	1115	1124	1110	1121	1106	1114	1117	1122	1125	1111	1122	1114	1120	1111	1122	1115
				1110	1132	1127	1121	1121	1117	1111	1125	1124	1118	1120	1111	1124	1115	1118	1124	1121	1115	1118	1121	1099	1110	1125	1129	1114	1120	1121	1114	1113	1129	1127	1113
				1110	1120	1117	1115	1118	1132	1118	1114	1121	1117	1122	1128	1114	1106	1125	1125	1124	1111	1127	1113	1122	1108	1115	1111	1118	1131	1115	1118	1114	1120	1113	1127
				1118	1118	1135	1120	1122	1122	1120	1110	1129	1124	1117	1124	1111	1121	1113	1117	1129	1124	1117	1120	1124	1097	1111	1121	1129	1113	1127	1118	1115	1118	1128	1128
				1118	1113	1122	1117	1115	1122	1127	1121	1124	1132	1120	1121	1128	1115	1110	1128	1110	1122	1118	1122	1114	1120	1107	1113	1111	1122	1124	1115	1122	1114	1120	1115
				1110	1122	1118	1135	1120	1121	1124	1120	1122	1114	1124	1118	1121	1107	1115	1113	1117	1125	1125	1115	1118	1125	1101	1115	1115	1139	1117	1127	1118	1113	1111	1118
				1107	1121	1121	1121	1115	1114	1118	1129	1115	1120	1127	1121	1122	1131	1114	1115	1124	1106	1124	1117	1124	1114	1122	1110	1122	1127	1122	1122	1129	1117	1113	1120
				1135	1108	1124	1114	1136	1115	1128	1122	1128	1124	1118	1125	1121	1120	1107	1108	1120	1114	1129	1121	1120	1121	1125	1118	1125	1125	1132	1117	1120	1118	1110	1114
				1099	1135	1120	1120	1121	1117	1118	1125	1118	1113	1121	1128	1118	1124	1134	1118	1121	1124	1106	1124	1115	1125	1111	1120	1131	1125	1117	1122	1121	1125	1118	1121
				1118	1121	1117	1120	1115	1135	1114	1110	1108	1122	1124	1121	1127	1120	1122	1108	1107	1124	1117	1129	1122	1118	1124	1118	1125	1122	1118	1136	1120	1121	1117	1113
				1115	1141	1129	1118	1117	1121	1115	1125	1128	1122	1113	1121	1131	1120	1120	1135	1125	1118	1124	1107	1124	1117	1118	1129	1122	1118	1127	1120	1120	1120	1120	1121
				1118	1129	1121	1120	1122	1117	1129	1121	1118	1115	1129	1122	1115	1125	1118	1121	1115	1107	1118	1115	1132	1121	1121	1124	1115	1122	1129	1122	1129	1118	1121	1129
				1111	1111	1142	1132	1117	1118	1120	1120	1127	1114	1120	1115	1115	1132	1120	1117	1114	1124	1120	1124	1107	1125	1127	1120	1115	1125	1132	1125	1122	1115	1120	1107
				1127	1111	1127	1118	1113	1122	1114	1131	1138	1115	1111	1122	1120	1111	1128	1120	1124	1115	1107	1118	1113	1128	1121	1108	1125	1124	1128	1128	1127	1129	1117	1117
				1124	1118	1110	1143	1127	1118	1118	1114	1129	1107	1118	1120	1114	1115	1134	1118	1122	1111	1128	1118	1121	1108	1121	1103	1115	1129	1118	1125	1121	1114	1113	1132
				1108	1125	1114	1127	1122	1127	1127	1121	1118	1107	1114	1114	1122	1121	1111	1129	1120	1125	1114	1107	1121	1122	1131	1120	1132	1111	1118	1131	1125	1122	1129	1110
				1120	1117	1124	1113	1138	1127	1113	1122	1122	1131	1113	1117	1122	1113	1117	1131	1122	1127	1111	1125	1117	1124	1107	1121	1118	1121	1124	1117	1136	1122	1111	1115
				1124	1131	1124	1111	1124	1120	1101	1127	1122	1121	1120	1117	1114	1124	1121	1108	1125	1118	1124	1114	1107	1125	1121	1121	1117	1121	1122	1115	1129	1125	1120	1125
				1117	1118	1120	1127	1114	1136	1117	1122	1127	1111	1135	1106	1115	1121	1114	1120	1101	1120	1128	1114	1124	1114	1117	1117	1117	1128	1121	1121	1118	1134	1122	1122
				1115	1122	1132	1122	1114	1124	1125	1131	1131	1110	1121	1121	1118	1120	1125	1121	1120	1124	1115	1121	1117	1111	1111	1124	1127	1120	1129	1124	1114	1132	1128	1128
				1125	1122	1121	1118	1122	1113	1128	1122	1125	1120	1115	1134	1101	1110	1121	1114	1125	1110	1118	1127	1110	1125	1111	1128	1114	1120	1118	1122	1118	1120	1132	1128
				1125	1101	1124	1134	1124	1113	1117	1107	1121	1113	1115	1120	1122	1118	1120	1125	1106	1122	1122	1110	1120	1115	1104	1124	1131	1120	1118	1129	1128	1117	1131	1111
				1121	1111	1122	1121	1120	1124	1115	1132	1127	1120	1121	1120	1129	1097	1108	1118	1128	1122	1127	1117	1132	1114	1125	1115	1135	1120	1114	1114	1118	1120	1117	1118
				1121	1111	1101	1122	1132	1124	1115	1127	1121	1129	1127	1111	1124	1118	1117	1115	1127	1110	1127	1128	1111	1111	1117	1127	1125	1117	1129	1121	1127	1127	1114	1120
				1113	1122	1108	1121	1118	1120	1121	1118	1117	1107	1122	1120	1114	1124	1100	1108	1121	1122	1124	1108	1115	1128	1113	1110	1125	1122	1118	1114	1114	1118	1120	1127
				1138	1122	1114	1111	1125	1131	1122	1114	1127	1111	1125	1128	1108	1129	1113	1120	1122	1127	1128	1129	1120	1113	1115	1120	1121	1115	1122	1127	1118	1128	1115	1122
				1124	1113	1122	1101	1125	1117	1122	1121	1106	1118	1103	1120	1111	1117	1121	1100	1118	1124	1121	1120	1138	1115	1128	1128	1104	1129	1127	1120	1111	1114	1121	1125
				1118	1117	1117	1113	1115	1121	1129	1114	1122	1125	1118	1127	1129	1108	1129	1118	1124	1118	1124	1135	1122	1117	1113	1122	1121	1128	1127	1127	1127	1121	1127	1104
				1128	1113	1118	1122	1103	1122	1113	1118	1125	1107	1114	1103	1117	1110	1111	1117	1117	1117	1124	1118	1118	1135	1113	1113	1127	1111	1129	1132	1120	1114	1114	1127
				1132	1108	1113	1113	1117	1118	1124	1122	1127	1107	1131	1117	1131	1132	1107	1129	1115	1122	1118	1124	1136	1124	1117	1122	1117	1124	1124	1122	1124	1135	1117	1124
				1127	1110	1118	1121	1124	1110	1121	1120	1128	1122	1106	1114	1099	1122	1113	1110	1129	1128	1125	1124	1113	1120	1139	1120	1135	1117	1108	1131	1134	1121	1114	1127
				1117	1117	1106	1108	1117	1114	1118	1120	1131	1127	1113	1132	1120	1127	1129	1111	1128	1111	1120	1118	1122	1134	1121	1120	1122	1113	1127	1122	1124	1124	1136	1117
				1125	1111	1114	1118	1135	1124	1110	1117	1115	1134	1121	1108	1115	1103	1122	1114	1125	1129	1129	1125	1122	1113	1115	1114	1117	1139	1128	1113	1129	1128	1120	1127
				1120	1124	1113	1111	1104	1115	1114	1129	1118	1136	1127	1114	1135	1117	1129	1125	1117	1132	1121	1113	1115	1120	1134	1121	1124	1124	1115	1128	1122	1125	1124	1100
				1111	1124	1107	1113	1118	1139	1127	1134	1115	1114	1131	1125	1108	1115	1101	1125	1132	1125	1129	1136	1131	1122	1113	1121	1128	1124	1138	1128	1107	1129	1132	1121
				1124	1122	1124	1110	1118	1103	1115	1131	1120	1113	1135	1125	1113	1136	1115	1131	1120	1107	1128	1125	1111	1114	1122	1121	1115	1108	1120	1113	1129	1125	1124	1107
				1124	1115	1124	1115	1122	1111	1132	1120	1117	1114	1124	1124	1122	1108	1117	1100	1107	1117	1118	1122	1131	1131	1121	1114	1121	1121	1120	1131	1125	1108	1128	1120
				1128	1122	1125	1122	1113	1138	1103	1122	1117	1122	1108	1127	1115	1117	1135	1120	1120	1132	1120	1122	1124	1106	1114	1117	1125	1117	1101	1118	1122	1124	1122	1125
				1121	1124	1117	1127	1125	1125	1111	1132	1107	1108	1115	1127	1121	1125	1107	1128	1121	1121	1110	1113	1108	1121	1122	1118	1121	1113	1110	1124	1117	1127	1111	1115
				1113	1127	1117	1117	1117	1125	1128	1129	1115	1128	1117	1121	1120	1117	1117	1127	1127	1113	1132	1131	1113	1121	1117	1124	1118	1111	1120	1121	1115	1128	1124	1128
				1120	1103	1118	1113	1118	1106	1111	1124	1115	1127	1127	1120	1118	1121	1117	1124	1125	1120	1114	1132	1125	1127	1110	1115	1114	1124	1131	1132	1121	1134	1117	1108
				3840 3840 3840>;

			PS_Config_Lmt_FW_Rawdata_N = <
				477	479	489	484	484	479	481	480	479	480	482	482	480	481	474	477	477	479	481	480	478	473	478	483	474	481	481	485	477	479	483	478
				472	483	481	483	483	481	478	481	482	486	480	477	475	479	480	483	481	483	480	485	476	472	478	481	475	480	481	479	482	486	481	480
				472	478	480	488	482	481	480	480	481	482	483	479	478	481	478	477	481	487	483	481	476	481	477	478	475	475	483	481	483	479	483	480
				480	482	483	481	485	482	480	481	478	480	482	473	480	481	480	481	478	481	479	481	482	477	480	482	479	477	479	477	480	484	485	477
				478	480	480	480	479	484	481	478	478	478	483	480	485	483	481	482	482	478	473	481	482	480	479	475	481	476	474	484	480	483	480	480
				484	477	481	484	479	482	480	480	479	483	481	472	478	482	486	479	480	480	481	475	480	478	480	486	475	479	478	480	477	481	482	473
				479	482	480	480	479	474	484	483	478	479	476	483	477	487	482	477	479	480	481	471	477	481	483	479	478	481	475	472	483	481	481	482
				484	477	478	481	484	478	481	476	478	480	481	481	474	480	482	481	478	481	475	480	474	477	478	481	482	476	481	477	480	476	481	478
				475	485	483	480	480	478	476	482	481	479	480	476	481	478	479	481	480	478	479	480	471	475	482	484	477	480	480	477	477	484	483	477
				475	480	478	478	479	485	479	477	480	478	481	483	477	474	482	482	481	476	483	477	481	475	478	476	479	484	478	479	477	480	477	483
				479	479	486	480	481	481	480	475	484	481	478	481	476	480	477	478	484	481	478	480	481	470	476	480	484	477	483	479	478	479	483	483
				479	477	481	478	478	481	483	480	481	485	480	480	483	478	475	483	475	481	479	481	477	480	474	477	476	481	481	478	481	477	480	478
				475	481	479	486	480	480	481	480	481	477	481	479	480	474	478	477	478	482	482	478	479	482	472	478	478	488	478	483	479	477	476	479
				474	480	480	480	478	477	479	484	478	480	483	480	481	484	477	478	481	474	481	478	481	477	481	475	481	483	481	481	484	478	477	480
				486	475	481	477	487	478	483	481	483	481	479	482	480	480	474	475	480	477	484	480	480	480	482	479	482	482	485	478	480	479	475	477
				471	486	480	480	480	478	479	482	479	477	480	483	479	481	486	479	480	481	474	481	478	482	476	480	484	482	478	481	480	482	479	480
				479	480	478	480	478	486	477	475	475	481	481	480	483	480	481	475	474	481	478	484	481	479	481	479	482	481	479	487	480	480	478	477
				478	489	484	479	478	480	478	482	483	481	477	480	484	480	480	486	482	479	481	474	481	478	479	484	481	479	483	480	480	480	480	480
				479	484	480	480	481	478	484	480	479	478	484	481	478	482	479	480	478	474	479	478	485	480	480	481	478	481	484	481	484	479	480	484
				476	476	489	485	478	479	480	480	483	477	480	478	478	485	480	478	477	481	480	481	474	482	483	480	478	482	485	482	481	478	480	474
				483	476	483	479	477	481	477	484	487	478	476	481	480	476	483	480	481	478	474	479	477	483	480	475	482	481	483	483	483	484	478	478
				481	479	475	490	483	479	479	477	484	474	479	480	477	478	486	479	481	476	483	479	480	475	480	472	478	484	479	482	480	477	477	485
				475	482	477	483	481	483	483	480	479	474	477	477	481	480	476	484	480	482	477	474	480	481	484	480	485	476	479	484	482	481	484	475
				480	478	481	477	487	483	477	481	481	484	477	478	481	477	478	484	481	483	476	482	478	481	474	480	479	480	481	478	487	481	476	478
				481	484	481	476	481	480	472	483	481	480	480	478	477	481	480	475	482	479	481	477	474	482	480	480	478	480	481	478	484	482	480	482
				478	479	480	483	477	487	478	481	483	476	486	474	478	480	477	480	472	480	483	477	481	477	478	478	478	483	480	480	479	486	481	481
				478	481	485	481	477	481	482	484	484	475	480	480	479	480	482	480	480	481	478	480	478	476	476	481	483	480	484	481	477	485	483	483
				482	481	480	479	481	477	483	481	482	480	478	486	472	475	480	477	482	475	479	483	475	482	476	483	477	480	479	481	479	480	485	483
				482	472	481	486	481	477	478	474	480	477	478	480	481	479	480	482	474	481	481	475	480	478	473	481	484	480	479	484	483	478	484	476
				480	476	481	480	480	481	478	485	483	480	480	480	484	470	475	479	483	481	483	478	485	477	482	478	486	480	477	477	479	480	478	479
				480	476	472	481	485	481	478	483	480	484	483	476	481	479	478	478	483	475	483	483	476	476	478	483	482	478	484	480	483	483	477	480
				477	481	475	480	479	480	480	479	478	474	481	480	477	481	471	475	480	481	481	475	478	483	477	475	482	481	479	477	477	479	480	483
				487	481	477	476	482	484	481	477	483	476	482	483	475	484	477	480	481	483	483	484	480	477	478	480	480	478	481	483	479	483	478	481
				481	477	481	472	482	478	481	480	474	479	472	480	476	478	480	471	479	481	480	480	487	478	483	483	473	484	483	480	476	477	480	482
				479	478	478	477	478	480	484	477	481	482	479	483	484	475	484	479	481	479	481	486	481	478	477	481	480	483	483	483	483	480	483	473
				483	477	479	481	472	481	477	479	482	474	477	472	478	475	476	478	478	478	481	479	479	486	477	477	483	476	484	485	480	477	477	483
				485	475	477	477	478	479	481	481	483	474	484	478	484	485	474	484	478	481	479	481	487	481	478	481	478	481	481	481	481	486	478	481
				483	475	479	480	481	475	480	480	483	481	474	477	471	481	477	475	484	483	482	481	477	480	488	480	486	478	475	484	486	480	477	483
				478	478	474	475	478	477	479	480	484	483	477	485	480	483	484	476	483	476	480	479	481	486	480	480	481	477	483	481	481	481	487	478
				482	476	477	479	486	481	475	478	478	486	480	475	478	472	481	477	482	484	484	482	481	477	478	477	478	488	483	477	484	483	480	483
				480	481	477	476	473	478	477	484	479	487	483	477	486	478	484	482	478	485	480	477	478	480	486	480	481	481	478	483	481	482	481	471
				476	481	474	477	479	488	483	486	478	477	484	482	475	478	472	482	485	482	484	487	484	481	477	480	483	481	487	483	474	484	485	480
				481	481	481	475	479	472	478	484	480	477	486	482	477	487	478	484	480	474	483	482	476	477	481	480	478	475	480	477	484	482	481	474
				481	478	481	478	481	476	485	480	478	477	481	481	481	475	478	471	474	478	479	481	484	484	480	477	480	480	480	484	482	475	483	480
				483	481	482	481	477	487	472	481	478	481	475	483	478	478	486	480	480	485	480	481	481	474	477	478	482	478	472	479	481	481	481	482
				480	481	478	483	482	482	476	485	474	475	478	483	480	482	474	483	480	480	475	477	475	480	481	479	480	477	475	481	478	483	476	478
				477	483	478	478	478	482	483	484	478	483	478	480	480	478	478	483	483	477	485	484	477	480	478	481	479	476	480	480	478	483	481	483
				480	472	479	477	479	474	476	481	478	483	483	480	479	480	478	481	482	480	477	485	482	483	475	478	477	481	484	485	480	486	478	475
				240 240 240>;

			PS_Config_Lmt_FW_CC_P = <
				96	91	96	97	97	97	97	96	97	97	97	97	97	97	99	97	97	91	96	97	97	97	97	97	99	97	97	97	97	97	97	96
				99	91	99	96	97	97	97	97	97	97	99	97	99	99	96	96	97	89	99	97	97	97	97	97	97	97	99	97	99	99	97	97
				100	95	91	96	97	97	97	97	97	97	97	97	97	96	97	100	99	95	91	96	97	97	97	97	99	99	97	97	97	97	99	100
				99	97	91	99	97	97	97	97	97	97	97	99	97	99	99	97	97	97	91	99	97	97	97	97	97	97	97	99	97	99	99	97
				100	97	95	91	96	97	97	97	96	99	97	97	97	97	97	97	99	97	96	91	96	97	97	97	97	99	99	97	97	97	97	99
				99	97	97	91	99	97	97	97	99	97	97	97	99	97	99	99	99	97	97	91	99	97	97	97	99	97	97	97	99	97	99	100
				99	99	97	95	91	96	99	97	99	97	99	97	97	97	99	97	99	99	97	96	91	96	99	97	99	97	99	99	97	97	99	97
				99	97	97	97	91	99	97	97	97	99	97	97	97	99	97	99	97	97	97	97	91	99	97	97	97	99	97	97	97	99	97	99
				100	99	99	97	96	91	96	99	97	99	96	99	97	97	97	99	99	99	99	97	96	91	96	99	97	99	97	99	99	97	97	99
				99	99	97	97	97	91	99	97	99	97	99	97	97	97	99	97	97	97	97	97	97	91	99	97	99	97	99	97	97	97	99	97
				97	99	99	99	97	96	91	96	97	97	99	96	99	97	97	97	97	99	99	99	97	96	91	96	97	97	99	97	99	99	97	97
				100	97	99	97	97	97	91	99	96	99	97	99	97	97	97	99	100	97	99	99	97	97	91	99	96	99	97	99	97	97	97	99
				97	97	99	99	99	97	96	91	97	97	97	99	97	99	97	97	97	97	99	99	99	97	96	91	97	97	97	99	97	99	99	97
				99	99	97	97	97	97	99	91	96	96	99	97	99	97	97	97	97	100	97	97	99	97	97	91	96	96	99	97	99	97	97	97
				97	97	97	99	99	99	97	95	96	97	97	97	99	97	99	99	97	97	97	99	99	99	97	96	97	97	97	97	99	97	99	99
				99	99	99	97	99	97	97	97	97	97	96	99	97	99	97	97	99	97	100	97	97	99	97	97	99	97	96	99	97	99	97	97
				97	97	97	97	99	99	99	97	96	97	97	97	97	99	97	99	97	97	97	97	99	99	99	97	96	97	97	97	97	99	97	99
				99	97	99	99	97	99	97	97	97	99	96	96	99	97	99	97	99	99	97	100	97	97	99	97	97	99	97	96	99	97	99	97
				99	97	97	97	97	99	99	99	97	96	97	97	97	97	99	97	99	97	97	97	97	99	99	99	99	97	97	97	97	97	99	97
				99	99	97	97	100	97	99	97	97	97	99	96	96	99	97	99	97	99	99	97	100	97	99	97	97	97	99	97	96	99	97	99
				99	99	97	97	97	97	100	97	96	97	96	97	99	97	97	99	99	99	97	97	97	97	99	99	96	99	96	97	97	97	97	99
				97	97	99	97	99	100	97	97	97	97	97	99	97	96	99	97	97	97	99	99	97	100	97	97	97	97	97	99	96	96	99	97
				97	99	99	97	97	97	97	99	97	96	97	96	97	99	97	97	97	99	99	97	97	97	97	99	97	97	99	96	97	97	97	97
				99	97	97	99	97	99	100	97	96	97	97	97	99	97	96	99	99	97	97	99	99	97	100	97	96	97	97	97	99	96	96	99
				97	97	99	99	97	97	97	97	97	97	96	97	96	97	99	99	97	97	99	99	97	97	97	97	97	97	97	99	96	97	97	99
				99	99	97	97	99	97	99	99	96	96	97	97	97	99	97	96	99	99	97	97	99	97	97	99	97	96	97	97	97	99	96	97
				97	97	97	99	99	97	97	97	97	97	97	96	97	96	97	99	97	97	97	99	99	97	97	97	97	97	97	96	99	96	97	97
				97	97	99	97	97	99	97	97	96	96	96	97	97	97	99	97	97	97	99	97	97	99	99	97	97	97	96	97	97	97	99	97
				99	97	97	97	99	99	97	97	96	97	97	97	96	97	96	97	99	97	97	97	99	99	97	97	96	97	97	97	96	99	96	97
				97	97	97	99	97	97	99	97	97	97	96	96	97	97	97	99	97	97	97	99	97	97	99	97	97	97	97	96	97	97	97	99
				97	99	97	97	97	99	99	97	97	96	97	97	97	96	97	96	97	99	97	97	97	99	99	97	97	96	97	97	97	96	99	97
				99	97	97	97	99	97	97	97	96	97	96	96	96	97	97	97	97	97	97	97	99	97	97	97	96	97	97	97	96	97	97	97
				99	97	99	97	97	97	99	97	96	97	96	97	97	97	96	97	99	97	99	97	97	97	99	97	96	97	96	97	97	97	97	99
				97	97	97	97	97	99	97	97	97	96	97	97	96	96	97	97	97	97	97	97	97	99	97	97	97	96	97	97	97	96	97	97
				97	99	97	99	97	97	97	99	91	96	97	96	97	97	97	96	96	99	97	97	97	97	97	99	91	96	97	96	97	97	97	97
				99	97	97	97	97	97	99	97	89	97	96	97	97	96	96	97	99	97	97	97	97	97	99	97	89	97	96	97	97	97	96	97
				97	97	99	97	99	97	97	97	96	91	96	97	96	97	97	97	97	96	99	97	97	97	97	97	96	91	96	97	96	97	97	97
				97	99	97	97	97	97	97	99	96	89	97	96	97	97	96	96	97	99	97	97	97	97	97	99	96	89	97	96	97	97	97	96
				97	96	96	99	97	97	97	96	97	95	91	96	97	96	97	97	97	97	96	99	97	97	97	97	97	96	91	96	97	96	97	97
				97	97	99	97	97	97	97	96	96	96	89	97	96	97	97	97	97	97	99	97	97	97	97	96	97	96	89	97	96	97	97	97
				97	97	96	96	99	97	97	96	97	97	95	91	96	97	96	97	97	97	96	96	97	97	97	97	97	97	96	91	96	97	96	99
				97	97	97	99	97	97	97	96	99	96	96	89	97	96	97	97	97	97	97	97	97	97	97	96	99	97	96	89	97	96	97	97
				97	97	97	96	96	99	97	97	97	97	97	95	91	96	97	96	97	97	97	96	96	97	97	97	97	97	97	96	91	96	97	96
				97	97	97	97	97	97	97	97	99	99	96	96	89	97	96	97	97	97	97	97	97	97	97	97	99	99	97	96	89	97	96	97
				99	97	96	97	96	96	97	97	97	96	97	97	95	91	96	97	97	97	97	97	96	96	97	97	97	96	97	97	95	91	96	99
				97	97	97	97	97	97	97	97	97	97	97	96	96	89	97	96	97	97	97	97	97	97	97	97	97	97	99	96	96	89	97	97
				96	97	97	96	96	96	96	97	96	97	96	97	97	95	91	96	96	97	96	96	97	96	96	97	96	97	96	97	97	95	91	97
				102	97	97	97	97	97	99	97	99	97	99	99	96	96	89	100	102	97	97	97	97	97	99	97	99	97	99	99	97	96	91	100
				314 314 314>;

			PS_Config_Lmt_FW_CC_N = <
				43	40	43	44	44	44	44	43	44	44	44	44	44	44	44	44	44	40	43	44	44	44	44	44	44	44	44	44	44	44	44	43
				44	40	44	43	44	44	44	44	44	44	44	44	44	44	43	43	44	40	44	44	44	44	44	44	44	44	44	44	44	44	44	44
				45	42	40	43	44	44	44	44	44	44	44	44	44	43	44	45	44	42	40	43	44	44	44	44	44	44	44	44	44	44	44	45
				44	44	40	44	44	44	44	44	44	44	44	44	44	44	44	44	44	44	40	44	44	44	44	44	44	44	44	44	44	44	44	44
				45	44	42	40	43	44	44	44	43	44	44	44	44	44	44	44	44	44	43	40	43	44	44	44	44	44	44	44	44	44	44	44
				44	44	44	40	44	44	44	44	44	44	44	44	44	44	44	44	44	44	44	40	44	44	44	44	44	44	44	44	44	44	44	45
				44	44	44	42	40	43	44	44	44	44	44	44	44	44	44	44	44	44	44	43	40	43	44	44	44	44	44	44	44	44	44	44
				44	44	44	44	40	44	44	44	44	44	44	44	44	44	44	44	44	44	44	44	40	44	44	44	44	44	44	44	44	44	44	44
				45	44	44	44	43	40	43	44	44	44	43	44	44	44	44	44	44	44	44	44	43	40	43	44	44	44	44	44	44	44	44	44
				44	44	44	44	44	40	44	44	44	44	44	44	44	44	44	44	44	44	44	44	44	40	44	44	44	44	44	44	44	44	44	44
				44	44	44	44	44	43	40	43	44	44	44	43	44	44	44	44	44	44	44	44	44	43	40	43	44	44	44	44	44	44	44	44
				45	44	44	44	44	44	40	44	43	44	44	44	44	44	44	44	45	44	44	44	44	44	40	44	43	44	44	44	44	44	44	44
				44	44	44	44	44	44	43	40	44	44	44	44	44	44	44	44	44	44	44	44	44	44	43	40	44	44	44	44	44	44	44	44
				44	44	44	44	44	44	44	40	43	43	44	44	44	44	44	44	44	45	44	44	44	44	44	40	43	43	44	44	44	44	44	44
				44	44	44	44	44	44	44	42	43	44	44	44	44	44	44	44	44	44	44	44	44	44	44	43	44	44	44	44	44	44	44	44
				44	44	44	44	44	44	44	44	44	44	43	44	44	44	44	44	44	44	45	44	44	44	44	44	44	44	43	44	44	44	44	44
				44	44	44	44	44	44	44	44	43	44	44	44	44	44	44	44	44	44	44	44	44	44	44	44	43	44	44	44	44	44	44	44
				44	44	44	44	44	44	44	44	44	44	43	43	44	44	44	44	44	44	44	45	44	44	44	44	44	44	44	43	44	44	44	44
				44	44	44	44	44	44	44	44	44	43	44	44	44	44	44	44	44	44	44	44	44	44	44	44	44	44	44	44	44	44	44	44
				44	44	44	44	45	44	44	44	44	44	44	43	43	44	44	44	44	44	44	44	45	44	44	44	44	44	44	44	43	44	44	44
				44	44	44	44	44	44	45	44	43	44	43	44	44	44	44	44	44	44	44	44	44	44	44	44	43	44	43	44	44	44	44	44
				44	44	44	44	44	45	44	44	44	44	44	44	44	43	44	44	44	44	44	44	44	45	44	44	44	44	44	44	43	43	44	44
				44	44	44	44	44	44	44	44	44	43	44	43	44	44	44	44	44	44	44	44	44	44	44	44	44	44	44	43	44	44	44	44
				44	44	44	44	44	44	45	44	43	44	44	44	44	44	43	44	44	44	44	44	44	44	45	44	43	44	44	44	44	43	43	44
				44	44	44	44	44	44	44	44	44	44	43	44	43	44	44	44	44	44	44	44	44	44	44	44	44	44	44	44	43	44	44	44
				44	44	44	44	44	44	44	44	43	43	44	44	44	44	44	43	44	44	44	44	44	44	44	44	44	43	44	44	44	44	43	44
				44	44	44	44	44	44	44	44	44	44	44	43	44	43	44	44	44	44	44	44	44	44	44	44	44	44	44	43	44	43	44	44
				44	44	44	44	44	44	44	44	43	43	43	44	44	44	44	44	44	44	44	44	44	44	44	44	44	44	43	44	44	44	44	44
				44	44	44	44	44	44	44	44	43	44	44	44	43	44	43	44	44	44	44	44	44	44	44	44	43	44	44	44	43	44	43	44
				44	44	44	44	44	44	44	44	44	44	43	43	44	44	44	44	44	44	44	44	44	44	44	44	44	44	44	43	44	44	44	44
				44	44	44	44	44	44	44	44	44	43	44	44	44	43	44	43	44	44	44	44	44	44	44	44	44	43	44	44	44	43	44	44
				44	44	44	44	44	44	44	44	43	44	43	43	43	44	44	44	44	44	44	44	44	44	44	44	43	44	44	44	43	44	44	44
				44	44	44	44	44	44	44	44	43	44	43	44	44	44	43	44	44	44	44	44	44	44	44	44	43	44	43	44	44	44	44	44
				44	44	44	44	44	44	44	44	44	43	44	44	43	43	44	44	44	44	44	44	44	44	44	44	44	43	44	44	44	43	44	44
				44	44	44	44	44	44	44	44	40	43	44	43	44	44	44	43	43	44	44	44	44	44	44	44	40	43	44	43	44	44	44	44
				44	44	44	44	44	44	44	44	40	44	43	44	44	43	43	44	44	44	44	44	44	44	44	44	40	44	43	44	44	44	43	44
				44	44	44	44	44	44	44	44	43	40	43	44	43	44	44	44	44	43	44	44	44	44	44	44	43	40	43	44	43	44	44	44
				44	44	44	44	44	44	44	44	43	40	44	43	44	44	43	43	44	44	44	44	44	44	44	44	43	40	44	43	44	44	44	43
				44	43	43	44	44	44	44	43	44	42	40	43	44	43	44	44	44	44	43	44	44	44	44	44	44	43	40	43	44	43	44	44
				44	44	44	44	44	44	44	43	43	43	40	44	43	44	44	44	44	44	44	44	44	44	44	43	44	43	40	44	43	44	44	44
				44	44	43	43	44	44	44	43	44	44	42	40	43	44	43	44	44	44	43	43	44	44	44	44	44	44	43	40	43	44	43	44
				44	44	44	44	44	44	44	43	44	43	43	40	44	43	44	44	44	44	44	44	44	44	44	43	44	44	43	40	44	43	44	44
				44	44	44	43	43	44	44	44	44	44	44	42	40	43	44	43	44	44	44	43	43	44	44	44	44	44	44	43	40	43	44	43
				44	44	44	44	44	44	44	44	44	44	43	43	40	44	43	44	44	44	44	44	44	44	44	44	44	44	44	43	40	44	43	44
				44	44	43	44	43	43	44	44	44	43	44	44	42	40	43	44	44	44	44	44	43	43	44	44	44	43	44	44	42	40	43	44
				44	44	44	44	44	44	44	44	44	44	44	43	43	40	44	43	44	44	44	44	44	44	44	44	44	44	44	43	43	40	44	44
				43	44	44	43	43	43	43	44	43	44	43	44	44	42	40	43	43	44	43	43	44	43	43	44	43	44	43	44	44	42	40	44
				45	44	44	44	44	44	44	44	44	44	44	44	43	43	40	45	45	44	44	44	44	44	44	44	44	44	44	44	44	43	40	45
				0 0 0>;

			PS_Config_Lmt_FW_Diff_P = <
				50	50	50	50	50	50	50	50	50	50	50	50	50	50	50	50	50	50	50	50	50	50	50	50	50	50	50	50	50	50	50	50
				50	50	50	50	50	50	50	50	50	50	50	50	50	50	50	50	50	50	50	50	50	50	50	50	50	50	50	50	50	50	50	50
				50	50	50	50	50	50	50	50	50	50	50	50	50	50	50	50	50	50	50	50	50	50	50	50	50	50	50	50	50	50	50	50
				50	50	50	50	50	50	50	50	50	50	50	50	50	50	50	50	50	50	50	50	50	50	50	50	50	50	50	50	50	50	50	50
				50	50	50	50	50	50	50	50	50	50	50	50	50	50	50	50	50	50	50	50	50	50	50	50	50	50	50	50	50	50	50	50
				50	50	50	50	50	50	50	50	50	50	50	50	50	50	50	50	50	50	50	50	50	50	50	50	50	50	50	50	50	50	50	50
				50	50	50	50	50	50	50	50	50	50	50	50	50	50	50	50	50	50	50	50	50	50	50	50	50	50	50	50	50	50	50	50
				50	50	50	50	50	50	50	50	50	50	50	50	50	50	50	50	50	50	50	50	50	50	50	50	50	50	50	50	50	50	50	50
				50	50	50	50	50	50	50	50	50	50	50	50	50	50	50	50	50	50	50	50	50	50	50	50	50	50	50	50	50	50	50	50
				50	50	50	50	50	50	50	50	50	50	50	50	50	50	50	50	50	50	50	50	50	50	50	50	50	50	50	50	50	50	50	50
				50	50	50	50	50	50	50	50	50	50	50	50	50	50	50	50	50	50	50	50	50	50	50	50	50	50	50	50	50	50	50	50
				50	50	50	50	50	50	50	50	50	50	50	50	50	50	50	50	50	50	50	50	50	50	50	50	50	50	50	50	50	50	50	50
				50	50	50	50	50	50	50	50	50	50	50	50	50	50	50	50	50	50	50	50	50	50	50	50	50	50	50	50	50	50	50	50
				50	50	50	50	50	50	50	50	50	50	50	50	50	50	50	50	50	50	50	50	50	50	50	50	50	50	50	50	50	50	50	50
				50	50	50	50	50	50	50	50	50	50	50	50	50	50	50	50	50	50	50	50	50	50	50	50	50	50	50	50	50	50	50	50
				50	50	50	50	50	50	50	50	50	50	50	50	50	50	50	50	50	50	50	50	50	50	50	50	50	50	50	50	50	50	50	50
				50	50	50	50	50	50	50	50	50	50	50	50	50	50	50	50	50	50	50	50	50	50	50	50	50	50	50	50	50	50	50	50
				50	50	50	50	50	50	50	50	50	50	50	50	50	50	50	50	50	50	50	50	50	50	50	50	50	50	50	50	50	50	50	50
				50	50	50	50	50	50	50	50	50	50	50	50	50	50	50	50	50	50	50	50	50	50	50	50	50	50	50	50	50	50	50	50
				50	50	50	50	50	50	50	50	50	50	50	50	50	50	50	50	50	50	50	50	50	50	50	50	50	50	50	50	50	50	50	50
				50	50	50	50	50	50	50	50	50	50	50	50	50	50	50	50	50	50	50	50	50	50	50	50	50	50	50	50	50	50	50	50
				50	50	50	50	50	50	50	50	50	50	50	50	50	50	50	50	50	50	50	50	50	50	50	50	50	50	50	50	50	50	50	50
				50	50	50	50	50	50	50	50	50	50	50	50	50	50	50	50	50	50	50	50	50	50	50	50	50	50	50	50	50	50	50	50
				50	50	50	50	50	50	50	50	50	50	50	50	50	50	50	50	50	50	50	50	50	50	50	50	50	50	50	50	50	50	50	50
				50	50	50	50	50	50	50	50	50	50	50	50	50	50	50	50	50	50	50	50	50	50	50	50	50	50	50	50	50	50	50	50
				50	50	50	50	50	50	50	50	50	50	50	50	50	50	50	50	50	50	50	50	50	50	50	50	50	50	50	50	50	50	50	50
				50	50	50	50	50	50	50	50	50	50	50	50	50	50	50	50	50	50	50	50	50	50	50	50	50	50	50	50	50	50	50	50
				50	50	50	50	50	50	50	50	50	50	50	50	50	50	50	50	50	50	50	50	50	50	50	50	50	50	50	50	50	50	50	50
				50	50	50	50	50	50	50	50	50	50	50	50	50	50	50	50	50	50	50	50	50	50	50	50	50	50	50	50	50	50	50	50
				50	50	50	50	50	50	50	50	50	50	50	50	50	50	50	50	50	50	50	50	50	50	50	50	50	50	50	50	50	50	50	50
				50	50	50	50	50	50	50	50	50	50	50	50	50	50	50	50	50	50	50	50	50	50	50	50	50	50	50	50	50	50	50	50
				50	50	50	50	50	50	50	50	50	50	50	50	50	50	50	50	50	50	50	50	50	50	50	50	50	50	50	50	50	50	50	50
				50	50	50	50	50	50	50	50	50	50	50	50	50	50	50	50	50	50	50	50	50	50	50	50	50	50	50	50	50	50	50	50
				50	50	50	50	50	50	50	50	50	50	50	50	50	50	50	50	50	50	50	50	50	50	50	50	50	50	50	50	50	50	50	50
				50	50	50	50	50	50	50	50	50	50	50	50	50	50	50	50	50	50	50	50	50	50	50	50	50	50	50	50	50	50	50	50
				50	50	50	50	50	50	50	50	50	50	50	50	50	50	50	50	50	50	50	50	50	50	50	50	50	50	50	50	50	50	50	50
				50	50	50	50	50	50	50	50	50	50	50	50	50	50	50	50	50	50	50	50	50	50	50	50	50	50	50	50	50	50	50	50
				50	50	50	50	50	50	50	50	50	50	50	50	50	50	50	50	50	50	50	50	50	50	50	50	50	50	50	50	50	50	50	50
				50	50	50	50	50	50	50	50	50	50	50	50	50	50	50	50	50	50	50	50	50	50	50	50	50	50	50	50	50	50	50	50
				50	50	50	50	50	50	50	50	50	50	50	50	50	50	50	50	50	50	50	50	50	50	50	50	50	50	50	50	50	50	50	50
				50	50	50	50	50	50	50	50	50	50	50	50	50	50	50	50	50	50	50	50	50	50	50	50	50	50	50	50	50	50	50	50
				50	50	50	50	50	50	50	50	50	50	50	50	50	50	50	50	50	50	50	50	50	50	50	50	50	50	50	50	50	50	50	50
				50	50	50	50	50	50	50	50	50	50	50	50	50	50	50	50	50	50	50	50	50	50	50	50	50	50	50	50	50	50	50	50
				50	50	50	50	50	50	50	50	50	50	50	50	50	50	50	50	50	50	50	50	50	50	50	50	50	50	50	50	50	50	50	50
				50	50	50	50	50	50	50	50	50	50	50	50	50	50	50	50	50	50	50	50	50	50	50	50	50	50	50	50	50	50	50	50
				50	50	50	50	50	50	50	50	50	50	50	50	50	50	50	50	50	50	50	50	50	50	50	50	50	50	50	50	50	50	50	50
				50	50	50	50	50	50	50	50	50	50	50	50	50	50	50	50	50	50	50	50	50	50	50	50	50	50	50	50	50	50	50	50
				50	50	50	50	50	50	50	50	50	50	50	50	50	50	50	50	50	50	50	50	50	50	50	50	50	50	50	50	50	50	50	50
				75 75 75>;

			PS_Config_Lmt_FW_Diff_N = <
				(-50)	(-50)	(-50)	(-50)	(-50)	(-50)	(-50)	(-50)	(-50)	(-50)	(-50)	(-50)	(-50)	(-50)	(-50)	(-50)	(-50)	(-50)	(-50)	(-50)	(-50)	(-50)	(-50)	(-50)	(-50)	(-50)	(-50)	(-50)	(-50)	(-50)	(-50)	(-50)
				(-50)	(-50)	(-50)	(-50)	(-50)	(-50)	(-50)	(-50)	(-50)	(-50)	(-50)	(-50)	(-50)	(-50)	(-50)	(-50)	(-50)	(-50)	(-50)	(-50)	(-50)	(-50)	(-50)	(-50)	(-50)	(-50)	(-50)	(-50)	(-50)	(-50)	(-50)	(-50)
				(-50)	(-50)	(-50)	(-50)	(-50)	(-50)	(-50)	(-50)	(-50)	(-50)	(-50)	(-50)	(-50)	(-50)	(-50)	(-50)	(-50)	(-50)	(-50)	(-50)	(-50)	(-50)	(-50)	(-50)	(-50)	(-50)	(-50)	(-50)	(-50)	(-50)	(-50)	(-50)
				(-50)	(-50)	(-50)	(-50)	(-50)	(-50)	(-50)	(-50)	(-50)	(-50)	(-50)	(-50)	(-50)	(-50)	(-50)	(-50)	(-50)	(-50)	(-50)	(-50)	(-50)	(-50)	(-50)	(-50)	(-50)	(-50)	(-50)	(-50)	(-50)	(-50)	(-50)	(-50)
				(-50)	(-50)	(-50)	(-50)	(-50)	(-50)	(-50)	(-50)	(-50)	(-50)	(-50)	(-50)	(-50)	(-50)	(-50)	(-50)	(-50)	(-50)	(-50)	(-50)	(-50)	(-50)	(-50)	(-50)	(-50)	(-50)	(-50)	(-50)	(-50)	(-50)	(-50)	(-50)
				(-50)	(-50)	(-50)	(-50)	(-50)	(-50)	(-50)	(-50)	(-50)	(-50)	(-50)	(-50)	(-50)	(-50)	(-50)	(-50)	(-50)	(-50)	(-50)	(-50)	(-50)	(-50)	(-50)	(-50)	(-50)	(-50)	(-50)	(-50)	(-50)	(-50)	(-50)	(-50)
				(-50)	(-50)	(-50)	(-50)	(-50)	(-50)	(-50)	(-50)	(-50)	(-50)	(-50)	(-50)	(-50)	(-50)	(-50)	(-50)	(-50)	(-50)	(-50)	(-50)	(-50)	(-50)	(-50)	(-50)	(-50)	(-50)	(-50)	(-50)	(-50)	(-50)	(-50)	(-50)
				(-50)	(-50)	(-50)	(-50)	(-50)	(-50)	(-50)	(-50)	(-50)	(-50)	(-50)	(-50)	(-50)	(-50)	(-50)	(-50)	(-50)	(-50)	(-50)	(-50)	(-50)	(-50)	(-50)	(-50)	(-50)	(-50)	(-50)	(-50)	(-50)	(-50)	(-50)	(-50)
				(-50)	(-50)	(-50)	(-50)	(-50)	(-50)	(-50)	(-50)	(-50)	(-50)	(-50)	(-50)	(-50)	(-50)	(-50)	(-50)	(-50)	(-50)	(-50)	(-50)	(-50)	(-50)	(-50)	(-50)	(-50)	(-50)	(-50)	(-50)	(-50)	(-50)	(-50)	(-50)
				(-50)	(-50)	(-50)	(-50)	(-50)	(-50)	(-50)	(-50)	(-50)	(-50)	(-50)	(-50)	(-50)	(-50)	(-50)	(-50)	(-50)	(-50)	(-50)	(-50)	(-50)	(-50)	(-50)	(-50)	(-50)	(-50)	(-50)	(-50)	(-50)	(-50)	(-50)	(-50)
				(-50)	(-50)	(-50)	(-50)	(-50)	(-50)	(-50)	(-50)	(-50)	(-50)	(-50)	(-50)	(-50)	(-50)	(-50)	(-50)	(-50)	(-50)	(-50)	(-50)	(-50)	(-50)	(-50)	(-50)	(-50)	(-50)	(-50)	(-50)	(-50)	(-50)	(-50)	(-50)
				(-50)	(-50)	(-50)	(-50)	(-50)	(-50)	(-50)	(-50)	(-50)	(-50)	(-50)	(-50)	(-50)	(-50)	(-50)	(-50)	(-50)	(-50)	(-50)	(-50)	(-50)	(-50)	(-50)	(-50)	(-50)	(-50)	(-50)	(-50)	(-50)	(-50)	(-50)	(-50)
				(-50)	(-50)	(-50)	(-50)	(-50)	(-50)	(-50)	(-50)	(-50)	(-50)	(-50)	(-50)	(-50)	(-50)	(-50)	(-50)	(-50)	(-50)	(-50)	(-50)	(-50)	(-50)	(-50)	(-50)	(-50)	(-50)	(-50)	(-50)	(-50)	(-50)	(-50)	(-50)
				(-50)	(-50)	(-50)	(-50)	(-50)	(-50)	(-50)	(-50)	(-50)	(-50)	(-50)	(-50)	(-50)	(-50)	(-50)	(-50)	(-50)	(-50)	(-50)	(-50)	(-50)	(-50)	(-50)	(-50)	(-50)	(-50)	(-50)	(-50)	(-50)	(-50)	(-50)	(-50)
				(-50)	(-50)	(-50)	(-50)	(-50)	(-50)	(-50)	(-50)	(-50)	(-50)	(-50)	(-50)	(-50)	(-50)	(-50)	(-50)	(-50)	(-50)	(-50)	(-50)	(-50)	(-50)	(-50)	(-50)	(-50)	(-50)	(-50)	(-50)	(-50)	(-50)	(-50)	(-50)
				(-50)	(-50)	(-50)	(-50)	(-50)	(-50)	(-50)	(-50)	(-50)	(-50)	(-50)	(-50)	(-50)	(-50)	(-50)	(-50)	(-50)	(-50)	(-50)	(-50)	(-50)	(-50)	(-50)	(-50)	(-50)	(-50)	(-50)	(-50)	(-50)	(-50)	(-50)	(-50)
				(-50)	(-50)	(-50)	(-50)	(-50)	(-50)	(-50)	(-50)	(-50)	(-50)	(-50)	(-50)	(-50)	(-50)	(-50)	(-50)	(-50)	(-50)	(-50)	(-50)	(-50)	(-50)	(-50)	(-50)	(-50)	(-50)	(-50)	(-50)	(-50)	(-50)	(-50)	(-50)
				(-50)	(-50)	(-50)	(-50)	(-50)	(-50)	(-50)	(-50)	(-50)	(-50)	(-50)	(-50)	(-50)	(-50)	(-50)	(-50)	(-50)	(-50)	(-50)	(-50)	(-50)	(-50)	(-50)	(-50)	(-50)	(-50)	(-50)	(-50)	(-50)	(-50)	(-50)	(-50)
				(-50)	(-50)	(-50)	(-50)	(-50)	(-50)	(-50)	(-50)	(-50)	(-50)	(-50)	(-50)	(-50)	(-50)	(-50)	(-50)	(-50)	(-50)	(-50)	(-50)	(-50)	(-50)	(-50)	(-50)	(-50)	(-50)	(-50)	(-50)	(-50)	(-50)	(-50)	(-50)
				(-50)	(-50)	(-50)	(-50)	(-50)	(-50)	(-50)	(-50)	(-50)	(-50)	(-50)	(-50)	(-50)	(-50)	(-50)	(-50)	(-50)	(-50)	(-50)	(-50)	(-50)	(-50)	(-50)	(-50)	(-50)	(-50)	(-50)	(-50)	(-50)	(-50)	(-50)	(-50)
				(-50)	(-50)	(-50)	(-50)	(-50)	(-50)	(-50)	(-50)	(-50)	(-50)	(-50)	(-50)	(-50)	(-50)	(-50)	(-50)	(-50)	(-50)	(-50)	(-50)	(-50)	(-50)	(-50)	(-50)	(-50)	(-50)	(-50)	(-50)	(-50)	(-50)	(-50)	(-50)
				(-50)	(-50)	(-50)	(-50)	(-50)	(-50)	(-50)	(-50)	(-50)	(-50)	(-50)	(-50)	(-50)	(-50)	(-50)	(-50)	(-50)	(-50)	(-50)	(-50)	(-50)	(-50)	(-50)	(-50)	(-50)	(-50)	(-50)	(-50)	(-50)	(-50)	(-50)	(-50)
				(-50)	(-50)	(-50)	(-50)	(-50)	(-50)	(-50)	(-50)	(-50)	(-50)	(-50)	(-50)	(-50)	(-50)	(-50)	(-50)	(-50)	(-50)	(-50)	(-50)	(-50)	(-50)	(-50)	(-50)	(-50)	(-50)	(-50)	(-50)	(-50)	(-50)	(-50)	(-50)
				(-50)	(-50)	(-50)	(-50)	(-50)	(-50)	(-50)	(-50)	(-50)	(-50)	(-50)	(-50)	(-50)	(-50)	(-50)	(-50)	(-50)	(-50)	(-50)	(-50)	(-50)	(-50)	(-50)	(-50)	(-50)	(-50)	(-50)	(-50)	(-50)	(-50)	(-50)	(-50)
				(-50)	(-50)	(-50)	(-50)	(-50)	(-50)	(-50)	(-50)	(-50)	(-50)	(-50)	(-50)	(-50)	(-50)	(-50)	(-50)	(-50)	(-50)	(-50)	(-50)	(-50)	(-50)	(-50)	(-50)	(-50)	(-50)	(-50)	(-50)	(-50)	(-50)	(-50)	(-50)
				(-50)	(-50)	(-50)	(-50)	(-50)	(-50)	(-50)	(-50)	(-50)	(-50)	(-50)	(-50)	(-50)	(-50)	(-50)	(-50)	(-50)	(-50)	(-50)	(-50)	(-50)	(-50)	(-50)	(-50)	(-50)	(-50)	(-50)	(-50)	(-50)	(-50)	(-50)	(-50)
				(-50)	(-50)	(-50)	(-50)	(-50)	(-50)	(-50)	(-50)	(-50)	(-50)	(-50)	(-50)	(-50)	(-50)	(-50)	(-50)	(-50)	(-50)	(-50)	(-50)	(-50)	(-50)	(-50)	(-50)	(-50)	(-50)	(-50)	(-50)	(-50)	(-50)	(-50)	(-50)
				(-50)	(-50)	(-50)	(-50)	(-50)	(-50)	(-50)	(-50)	(-50)	(-50)	(-50)	(-50)	(-50)	(-50)	(-50)	(-50)	(-50)	(-50)	(-50)	(-50)	(-50)	(-50)	(-50)	(-50)	(-50)	(-50)	(-50)	(-50)	(-50)	(-50)	(-50)	(-50)
				(-50)	(-50)	(-50)	(-50)	(-50)	(-50)	(-50)	(-50)	(-50)	(-50)	(-50)	(-50)	(-50)	(-50)	(-50)	(-50)	(-50)	(-50)	(-50)	(-50)	(-50)	(-50)	(-50)	(-50)	(-50)	(-50)	(-50)	(-50)	(-50)	(-50)	(-50)	(-50)
				(-50)	(-50)	(-50)	(-50)	(-50)	(-50)	(-50)	(-50)	(-50)	(-50)	(-50)	(-50)	(-50)	(-50)	(-50)	(-50)	(-50)	(-50)	(-50)	(-50)	(-50)	(-50)	(-50)	(-50)	(-50)	(-50)	(-50)	(-50)	(-50)	(-50)	(-50)	(-50)
				(-50)	(-50)	(-50)	(-50)	(-50)	(-50)	(-50)	(-50)	(-50)	(-50)	(-50)	(-50)	(-50)	(-50)	(-50)	(-50)	(-50)	(-50)	(-50)	(-50)	(-50)	(-50)	(-50)	(-50)	(-50)	(-50)	(-50)	(-50)	(-50)	(-50)	(-50)	(-50)
				(-50)	(-50)	(-50)	(-50)	(-50)	(-50)	(-50)	(-50)	(-50)	(-50)	(-50)	(-50)	(-50)	(-50)	(-50)	(-50)	(-50)	(-50)	(-50)	(-50)	(-50)	(-50)	(-50)	(-50)	(-50)	(-50)	(-50)	(-50)	(-50)	(-50)	(-50)	(-50)
				(-50)	(-50)	(-50)	(-50)	(-50)	(-50)	(-50)	(-50)	(-50)	(-50)	(-50)	(-50)	(-50)	(-50)	(-50)	(-50)	(-50)	(-50)	(-50)	(-50)	(-50)	(-50)	(-50)	(-50)	(-50)	(-50)	(-50)	(-50)	(-50)	(-50)	(-50)	(-50)
				(-50)	(-50)	(-50)	(-50)	(-50)	(-50)	(-50)	(-50)	(-50)	(-50)	(-50)	(-50)	(-50)	(-50)	(-50)	(-50)	(-50)	(-50)	(-50)	(-50)	(-50)	(-50)	(-50)	(-50)	(-50)	(-50)	(-50)	(-50)	(-50)	(-50)	(-50)	(-50)
				(-50)	(-50)	(-50)	(-50)	(-50)	(-50)	(-50)	(-50)	(-50)	(-50)	(-50)	(-50)	(-50)	(-50)	(-50)	(-50)	(-50)	(-50)	(-50)	(-50)	(-50)	(-50)	(-50)	(-50)	(-50)	(-50)	(-50)	(-50)	(-50)	(-50)	(-50)	(-50)
				(-50)	(-50)	(-50)	(-50)	(-50)	(-50)	(-50)	(-50)	(-50)	(-50)	(-50)	(-50)	(-50)	(-50)	(-50)	(-50)	(-50)	(-50)	(-50)	(-50)	(-50)	(-50)	(-50)	(-50)	(-50)	(-50)	(-50)	(-50)	(-50)	(-50)	(-50)	(-50)
				(-50)	(-50)	(-50)	(-50)	(-50)	(-50)	(-50)	(-50)	(-50)	(-50)	(-50)	(-50)	(-50)	(-50)	(-50)	(-50)	(-50)	(-50)	(-50)	(-50)	(-50)	(-50)	(-50)	(-50)	(-50)	(-50)	(-50)	(-50)	(-50)	(-50)	(-50)	(-50)
				(-50)	(-50)	(-50)	(-50)	(-50)	(-50)	(-50)	(-50)	(-50)	(-50)	(-50)	(-50)	(-50)	(-50)	(-50)	(-50)	(-50)	(-50)	(-50)	(-50)	(-50)	(-50)	(-50)	(-50)	(-50)	(-50)	(-50)	(-50)	(-50)	(-50)	(-50)	(-50)
				(-50)	(-50)	(-50)	(-50)	(-50)	(-50)	(-50)	(-50)	(-50)	(-50)	(-50)	(-50)	(-50)	(-50)	(-50)	(-50)	(-50)	(-50)	(-50)	(-50)	(-50)	(-50)	(-50)	(-50)	(-50)	(-50)	(-50)	(-50)	(-50)	(-50)	(-50)	(-50)
				(-50)	(-50)	(-50)	(-50)	(-50)	(-50)	(-50)	(-50)	(-50)	(-50)	(-50)	(-50)	(-50)	(-50)	(-50)	(-50)	(-50)	(-50)	(-50)	(-50)	(-50)	(-50)	(-50)	(-50)	(-50)	(-50)	(-50)	(-50)	(-50)	(-50)	(-50)	(-50)
				(-50)	(-50)	(-50)	(-50)	(-50)	(-50)	(-50)	(-50)	(-50)	(-50)	(-50)	(-50)	(-50)	(-50)	(-50)	(-50)	(-50)	(-50)	(-50)	(-50)	(-50)	(-50)	(-50)	(-50)	(-50)	(-50)	(-50)	(-50)	(-50)	(-50)	(-50)	(-50)
				(-50)	(-50)	(-50)	(-50)	(-50)	(-50)	(-50)	(-50)	(-50)	(-50)	(-50)	(-50)	(-50)	(-50)	(-50)	(-50)	(-50)	(-50)	(-50)	(-50)	(-50)	(-50)	(-50)	(-50)	(-50)	(-50)	(-50)	(-50)	(-50)	(-50)	(-50)	(-50)
				(-50)	(-50)	(-50)	(-50)	(-50)	(-50)	(-50)	(-50)	(-50)	(-50)	(-50)	(-50)	(-50)	(-50)	(-50)	(-50)	(-50)	(-50)	(-50)	(-50)	(-50)	(-50)	(-50)	(-50)	(-50)	(-50)	(-50)	(-50)	(-50)	(-50)	(-50)	(-50)
				(-50)	(-50)	(-50)	(-50)	(-50)	(-50)	(-50)	(-50)	(-50)	(-50)	(-50)	(-50)	(-50)	(-50)	(-50)	(-50)	(-50)	(-50)	(-50)	(-50)	(-50)	(-50)	(-50)	(-50)	(-50)	(-50)	(-50)	(-50)	(-50)	(-50)	(-50)	(-50)
				(-50)	(-50)	(-50)	(-50)	(-50)	(-50)	(-50)	(-50)	(-50)	(-50)	(-50)	(-50)	(-50)	(-50)	(-50)	(-50)	(-50)	(-50)	(-50)	(-50)	(-50)	(-50)	(-50)	(-50)	(-50)	(-50)	(-50)	(-50)	(-50)	(-50)	(-50)	(-50)
				(-50)	(-50)	(-50)	(-50)	(-50)	(-50)	(-50)	(-50)	(-50)	(-50)	(-50)	(-50)	(-50)	(-50)	(-50)	(-50)	(-50)	(-50)	(-50)	(-50)	(-50)	(-50)	(-50)	(-50)	(-50)	(-50)	(-50)	(-50)	(-50)	(-50)	(-50)	(-50)
				(-50)	(-50)	(-50)	(-50)	(-50)	(-50)	(-50)	(-50)	(-50)	(-50)	(-50)	(-50)	(-50)	(-50)	(-50)	(-50)	(-50)	(-50)	(-50)	(-50)	(-50)	(-50)	(-50)	(-50)	(-50)	(-50)	(-50)	(-50)	(-50)	(-50)	(-50)	(-50)
				(-50)	(-50)	(-50)	(-50)	(-50)	(-50)	(-50)	(-50)	(-50)	(-50)	(-50)	(-50)	(-50)	(-50)	(-50)	(-50)	(-50)	(-50)	(-50)	(-50)	(-50)	(-50)	(-50)	(-50)	(-50)	(-50)	(-50)	(-50)	(-50)	(-50)	(-50)	(-50)
				(-75) (-75) (-75)>;

			PS_Config_Diff_Test_Frame = <50>;

			PS_Config_Lmt_LPWG_Rawdata_P = <
				3840 3840 3840 3840 3840 3840 3840 3840 3840 3840 3840 3840 3840 3840 3840 3840 3840 3840 3840 3840 3840 3840 3840 3840 3840 3840 3840 3840 3840 3840 3840 3840
				3840 3840 3840 3840 3840 3840 3840 3840 3840 3840 3840 3840 3840 3840 3840 3840 3840 3840 3840 3840 3840 3840 3840 3840 3840 3840 3840 3840 3840 3840 3840 3840
				3840 3840 3840 3840 3840 3840 3840 3840 3840 3840 3840 3840 3840 3840 3840 3840 3840 3840 3840 3840 3840 3840 3840 3840 3840 3840 3840 3840 3840 3840 3840 3840
				3840 3840 3840 3840 3840 3840 3840 3840 3840 3840 3840 3840 3840 3840 3840 3840 3840 3840 3840 3840 3840 3840 3840 3840 3840 3840 3840 3840 3840 3840 3840 3840
				3840 3840 3840 3840 3840 3840 3840 3840 3840 3840 3840 3840 3840 3840 3840 3840 3840 3840 3840 3840 3840 3840 3840 3840 3840 3840 3840 3840 3840 3840 3840 3840
				3840 3840 3840 3840 3840 3840 3840 3840 3840 3840 3840 3840 3840 3840 3840 3840 3840 3840 3840 3840 3840 3840 3840 3840 3840 3840 3840 3840 3840 3840 3840 3840
				3840 3840 3840 3840 3840 3840 3840 3840 3840 3840 3840 3840 3840 3840 3840 3840 3840 3840 3840 3840 3840 3840 3840 3840 3840 3840 3840 3840 3840 3840 3840 3840
				3840 3840 3840 3840 3840 3840 3840 3840 3840 3840 3840 3840 3840 3840 3840 3840 3840 3840 3840 3840 3840 3840 3840 3840 3840 3840 3840 3840 3840 3840 3840 3840
				3840 3840 3840 3840 3840 3840 3840 3840 3840 3840 3840 3840 3840 3840 3840 3840 3840 3840 3840 3840 3840 3840 3840 3840 3840 3840 3840 3840 3840 3840 3840 3840
				3840 3840 3840 3840 3840 3840 3840 3840 3840 3840 3840 3840 3840 3840 3840 3840 3840 3840 3840 3840 3840 3840 3840 3840 3840 3840 3840 3840 3840 3840 3840 3840
				3840 3840 3840 3840 3840 3840 3840 3840 3840 3840 3840 3840 3840 3840 3840 3840 3840 3840 3840 3840 3840 3840 3840 3840 3840 3840 3840 3840 3840 3840 3840 3840
				3840 3840 3840 3840 3840 3840 3840 3840 3840 3840 3840 3840 3840 3840 3840 3840 3840 3840 3840 3840 3840 3840 3840 3840 3840 3840 3840 3840 3840 3840 3840 3840
				3840 3840 3840 3840 3840 3840 3840 3840 3840 3840 3840 3840 3840 3840 3840 3840 3840 3840 3840 3840 3840 3840 3840 3840 3840 3840 3840 3840 3840 3840 3840 3840
				3840 3840 3840 3840 3840 3840 3840 3840 3840 3840 3840 3840 3840 3840 3840 3840 3840 3840 3840 3840 3840 3840 3840 3840 3840 3840 3840 3840 3840 3840 3840 3840
				3840 3840 3840 3840 3840 3840 3840 3840 3840 3840 3840 3840 3840 3840 3840 3840 3840 3840 3840 3840 3840 3840 3840 3840 3840 3840 3840 3840 3840 3840 3840 3840
				3840 3840 3840 3840 3840 3840 3840 3840 3840 3840 3840 3840 3840 3840 3840 3840 3840 3840 3840 3840 3840 3840 3840 3840 3840 3840 3840 3840 3840 3840 3840 3840
				3840 3840 3840 3840 3840 3840 3840 3840 3840 3840 3840 3840 3840 3840 3840 3840 3840 3840 3840 3840 3840 3840 3840 3840 3840 3840 3840 3840 3840 3840 3840 3840
				3840 3840 3840 3840 3840 3840 3840 3840 3840 3840 3840 3840 3840 3840 3840 3840 3840 3840 3840 3840 3840 3840 3840 3840 3840 3840 3840 3840 3840 3840 3840 3840
				3840 3840 3840 3840 3840 3840 3840 3840 3840 3840 3840 3840 3840 3840 3840 3840 3840 3840 3840 3840 3840 3840 3840 3840 3840 3840 3840 3840 3840 3840 3840 3840
				3840 3840 3840 3840 3840 3840 3840 3840 3840 3840 3840 3840 3840 3840 3840 3840 3840 3840 3840 3840 3840 3840 3840 3840 3840 3840 3840 3840 3840 3840 3840 3840
				3840 3840 3840 3840 3840 3840 3840 3840 3840 3840 3840 3840 3840 3840 3840 3840 3840 3840 3840 3840 3840 3840 3840 3840 3840 3840 3840 3840 3840 3840 3840 3840
				3840 3840 3840 3840 3840 3840 3840 3840 3840 3840 3840 3840 3840 3840 3840 3840 3840 3840 3840 3840 3840 3840 3840 3840 3840 3840 3840 3840 3840 3840 3840 3840
				3840 3840 3840 3840 3840 3840 3840 3840 3840 3840 3840 3840 3840 3840 3840 3840 3840 3840 3840 3840 3840 3840 3840 3840 3840 3840 3840 3840 3840 3840 3840 3840
				3840 3840 3840 3840 3840 3840 3840 3840 3840 3840 3840 3840 3840 3840 3840 3840 3840 3840 3840 3840 3840 3840 3840 3840 3840 3840 3840 3840 3840 3840 3840 3840
				3840 3840 3840 3840 3840 3840 3840 3840 3840 3840 3840 3840 3840 3840 3840 3840 3840 3840 3840 3840 3840 3840 3840 3840 3840 3840 3840 3840 3840 3840 3840 3840
				3840 3840 3840 3840 3840 3840 3840 3840 3840 3840 3840 3840 3840 3840 3840 3840 3840 3840 3840 3840 3840 3840 3840 3840 3840 3840 3840 3840 3840 3840 3840 3840
				3840 3840 3840 3840 3840 3840 3840 3840 3840 3840 3840 3840 3840 3840 3840 3840 3840 3840 3840 3840 3840 3840 3840 3840 3840 3840 3840 3840 3840 3840 3840 3840
				3840 3840 3840 3840 3840 3840 3840 3840 3840 3840 3840 3840 3840 3840 3840 3840 3840 3840 3840 3840 3840 3840 3840 3840 3840 3840 3840 3840 3840 3840 3840 3840
				3840 3840 3840 3840 3840 3840 3840 3840 3840 3840 3840 3840 3840 3840 3840 3840 3840 3840 3840 3840 3840 3840 3840 3840 3840 3840 3840 3840 3840 3840 3840 3840
				3840 3840 3840 3840 3840 3840 3840 3840 3840 3840 3840 3840 3840 3840 3840 3840 3840 3840 3840 3840 3840 3840 3840 3840 3840 3840 3840 3840 3840 3840 3840 3840
				3840 3840 3840 3840 3840 3840 3840 3840 3840 3840 3840 3840 3840 3840 3840 3840 3840 3840 3840 3840 3840 3840 3840 3840 3840 3840 3840 3840 3840 3840 3840 3840
				3840 3840 3840 3840 3840 3840 3840 3840 3840 3840 3840 3840 3840 3840 3840 3840 3840 3840 3840 3840 3840 3840 3840 3840 3840 3840 3840 3840 3840 3840 3840 3840
				3840 3840 3840 3840 3840 3840 3840 3840 3840 3840 3840 3840 3840 3840 3840 3840 3840 3840 3840 3840 3840 3840 3840 3840 3840 3840 3840 3840 3840 3840 3840 3840
				3840 3840 3840 3840 3840 3840 3840 3840 3840 3840 3840 3840 3840 3840 3840 3840 3840 3840 3840 3840 3840 3840 3840 3840 3840 3840 3840 3840 3840 3840 3840 3840
				3840 3840 3840 3840 3840 3840 3840 3840 3840 3840 3840 3840 3840 3840 3840 3840 3840 3840 3840 3840 3840 3840 3840 3840 3840 3840 3840 3840 3840 3840 3840 3840
				3840 3840 3840 3840 3840 3840 3840 3840 3840 3840 3840 3840 3840 3840 3840 3840 3840 3840 3840 3840 3840 3840 3840 3840 3840 3840 3840 3840 3840 3840 3840 3840
				3840 3840 3840 3840 3840 3840 3840 3840 3840 3840 3840 3840 3840 3840 3840 3840 3840 3840 3840 3840 3840 3840 3840 3840 3840 3840 3840 3840 3840 3840 3840 3840
				3840 3840 3840 3840 3840 3840 3840 3840 3840 3840 3840 3840 3840 3840 3840 3840 3840 3840 3840 3840 3840 3840 3840 3840 3840 3840 3840 3840 3840 3840 3840 3840
				3840 3840 3840 3840 3840 3840 3840 3840 3840 3840 3840 3840 3840 3840 3840 3840 3840 3840 3840 3840 3840 3840 3840 3840 3840 3840 3840 3840 3840 3840 3840 3840
				3840 3840 3840 3840 3840 3840 3840 3840 3840 3840 3840 3840 3840 3840 3840 3840 3840 3840 3840 3840 3840 3840 3840 3840 3840 3840 3840 3840 3840 3840 3840 3840
				3840 3840 3840 3840 3840 3840 3840 3840 3840 3840 3840 3840 3840 3840 3840 3840 3840 3840 3840 3840 3840 3840 3840 3840 3840 3840 3840 3840 3840 3840 3840 3840
				3840 3840 3840 3840 3840 3840 3840 3840 3840 3840 3840 3840 3840 3840 3840 3840 3840 3840 3840 3840 3840 3840 3840 3840 3840 3840 3840 3840 3840 3840 3840 3840
				3840 3840 3840 3840 3840 3840 3840 3840 3840 3840 3840 3840 3840 3840 3840 3840 3840 3840 3840 3840 3840 3840 3840 3840 3840 3840 3840 3840 3840 3840 3840 3840
				3840 3840 3840 3840 3840 3840 3840 3840 3840 3840 3840 3840 3840 3840 3840 3840 3840 3840 3840 3840 3840 3840 3840 3840 3840 3840 3840 3840 3840 3840 3840 3840
				3840 3840 3840 3840 3840 3840 3840 3840 3840 3840 3840 3840 3840 3840 3840 3840 3840 3840 3840 3840 3840 3840 3840 3840 3840 3840 3840 3840 3840 3840 3840 3840
				3840 3840 3840 3840 3840 3840 3840 3840 3840 3840 3840 3840 3840 3840 3840 3840 3840 3840 3840 3840 3840 3840 3840 3840 3840 3840 3840 3840 3840 3840 3840 3840
				3840 3840 3840 3840 3840 3840 3840 3840 3840 3840 3840 3840 3840 3840 3840 3840 3840 3840 3840 3840 3840 3840 3840 3840 3840 3840 3840 3840 3840 3840 3840 3840
				3840 3840 3840 3840 3840 3840 3840 3840 3840 3840 3840 3840 3840 3840 3840 3840 3840 3840 3840 3840 3840 3840 3840 3840 3840 3840 3840 3840 3840 3840 3840 3840
				3840 3840 3840 3840 3840 3840 3840 3840 3840 3840 3840 3840 3840 3840 3840 3840 3840 3840 3840 3840 3840 3840 3840 3840 3840 3840 3840 3840 3840 3840 3840 3840
				3840 3840 3840 3840 3840 3840 3840 3840 3840 3840 3840 3840 3840 3840 3840 3840 3840 3840 3840 3840 3840 3840 3840 3840 3840 3840 3840 3840 3840 3840 3840 3840
				3840 3840 3840>;

			PS_Config_Lmt_LPWG_Rawdata_N = <
				240 240 240 240 240 240 240 240 240 240 240 240 240 240 240 240 240 240 240 240 240 240 240 240 240 240 240 240 240 240 240 240
				240 240 240 240 240 240 240 240 240 240 240 240 240 240 240 240 240 240 240 240 240 240 240 240 240 240 240 240 240 240 240 240
				240 240 240 240 240 240 240 240 240 240 240 240 240 240 240 240 240 240 240 240 240 240 240 240 240 240 240 240 240 240 240 240
				240 240 240 240 240 240 240 240 240 240 240 240 240 240 240 240 240 240 240 240 240 240 240 240 240 240 240 240 240 240 240 240
				240 240 240 240 240 240 240 240 240 240 240 240 240 240 240 240 240 240 240 240 240 240 240 240 240 240 240 240 240 240 240 240
				240 240 240 240 240 240 240 240 240 240 240 240 240 240 240 240 240 240 240 240 240 240 240 240 240 240 240 240 240 240 240 240
				240 240 240 240 240 240 240 240 240 240 240 240 240 240 240 240 240 240 240 240 240 240 240 240 240 240 240 240 240 240 240 240
				240 240 240 240 240 240 240 240 240 240 240 240 240 240 240 240 240 240 240 240 240 240 240 240 240 240 240 240 240 240 240 240
				240 240 240 240 240 240 240 240 240 240 240 240 240 240 240 240 240 240 240 240 240 240 240 240 240 240 240 240 240 240 240 240
				240 240 240 240 240 240 240 240 240 240 240 240 240 240 240 240 240 240 240 240 240 240 240 240 240 240 240 240 240 240 240 240
				240 240 240 240 240 240 240 240 240 240 240 240 240 240 240 240 240 240 240 240 240 240 240 240 240 240 240 240 240 240 240 240
				240 240 240 240 240 240 240 240 240 240 240 240 240 240 240 240 240 240 240 240 240 240 240 240 240 240 240 240 240 240 240 240
				240 240 240 240 240 240 240 240 240 240 240 240 240 240 240 240 240 240 240 240 240 240 240 240 240 240 240 240 240 240 240 240
				240 240 240 240 240 240 240 240 240 240 240 240 240 240 240 240 240 240 240 240 240 240 240 240 240 240 240 240 240 240 240 240
				240 240 240 240 240 240 240 240 240 240 240 240 240 240 240 240 240 240 240 240 240 240 240 240 240 240 240 240 240 240 240 240
				240 240 240 240 240 240 240 240 240 240 240 240 240 240 240 240 240 240 240 240 240 240 240 240 240 240 240 240 240 240 240 240
				240 240 240 240 240 240 240 240 240 240 240 240 240 240 240 240 240 240 240 240 240 240 240 240 240 240 240 240 240 240 240 240
				240 240 240 240 240 240 240 240 240 240 240 240 240 240 240 240 240 240 240 240 240 240 240 240 240 240 240 240 240 240 240 240
				240 240 240 240 240 240 240 240 240 240 240 240 240 240 240 240 240 240 240 240 240 240 240 240 240 240 240 240 240 240 240 240
				240 240 240 240 240 240 240 240 240 240 240 240 240 240 240 240 240 240 240 240 240 240 240 240 240 240 240 240 240 240 240 240
				240 240 240 240 240 240 240 240 240 240 240 240 240 240 240 240 240 240 240 240 240 240 240 240 240 240 240 240 240 240 240 240
				240 240 240 240 240 240 240 240 240 240 240 240 240 240 240 240 240 240 240 240 240 240 240 240 240 240 240 240 240 240 240 240
				240 240 240 240 240 240 240 240 240 240 240 240 240 240 240 240 240 240 240 240 240 240 240 240 240 240 240 240 240 240 240 240
				240 240 240 240 240 240 240 240 240 240 240 240 240 240 240 240 240 240 240 240 240 240 240 240 240 240 240 240 240 240 240 240
				240 240 240 240 240 240 240 240 240 240 240 240 240 240 240 240 240 240 240 240 240 240 240 240 240 240 240 240 240 240 240 240
				240 240 240 240 240 240 240 240 240 240 240 240 240 240 240 240 240 240 240 240 240 240 240 240 240 240 240 240 240 240 240 240
				240 240 240 240 240 240 240 240 240 240 240 240 240 240 240 240 240 240 240 240 240 240 240 240 240 240 240 240 240 240 240 240
				240 240 240 240 240 240 240 240 240 240 240 240 240 240 240 240 240 240 240 240 240 240 240 240 240 240 240 240 240 240 240 240
				240 240 240 240 240 240 240 240 240 240 240 240 240 240 240 240 240 240 240 240 240 240 240 240 240 240 240 240 240 240 240 240
				240 240 240 240 240 240 240 240 240 240 240 240 240 240 240 240 240 240 240 240 240 240 240 240 240 240 240 240 240 240 240 240
				240 240 240 240 240 240 240 240 240 240 240 240 240 240 240 240 240 240 240 240 240 240 240 240 240 240 240 240 240 240 240 240
				240 240 240 240 240 240 240 240 240 240 240 240 240 240 240 240 240 240 240 240 240 240 240 240 240 240 240 240 240 240 240 240
				240 240 240 240 240 240 240 240 240 240 240 240 240 240 240 240 240 240 240 240 240 240 240 240 240 240 240 240 240 240 240 240
				240 240 240 240 240 240 240 240 240 240 240 240 240 240 240 240 240 240 240 240 240 240 240 240 240 240 240 240 240 240 240 240
				240 240 240 240 240 240 240 240 240 240 240 240 240 240 240 240 240 240 240 240 240 240 240 240 240 240 240 240 240 240 240 240
				240 240 240 240 240 240 240 240 240 240 240 240 240 240 240 240 240 240 240 240 240 240 240 240 240 240 240 240 240 240 240 240
				240 240 240 240 240 240 240 240 240 240 240 240 240 240 240 240 240 240 240 240 240 240 240 240 240 240 240 240 240 240 240 240
				240 240 240 240 240 240 240 240 240 240 240 240 240 240 240 240 240 240 240 240 240 240 240 240 240 240 240 240 240 240 240 240
				240 240 240 240 240 240 240 240 240 240 240 240 240 240 240 240 240 240 240 240 240 240 240 240 240 240 240 240 240 240 240 240
				240 240 240 240 240 240 240 240 240 240 240 240 240 240 240 240 240 240 240 240 240 240 240 240 240 240 240 240 240 240 240 240
				240 240 240 240 240 240 240 240 240 240 240 240 240 240 240 240 240 240 240 240 240 240 240 240 240 240 240 240 240 240 240 240
				240 240 240 240 240 240 240 240 240 240 240 240 240 240 240 240 240 240 240 240 240 240 240 240 240 240 240 240 240 240 240 240
				240 240 240 240 240 240 240 240 240 240 240 240 240 240 240 240 240 240 240 240 240 240 240 240 240 240 240 240 240 240 240 240
				240 240 240 240 240 240 240 240 240 240 240 240 240 240 240 240 240 240 240 240 240 240 240 240 240 240 240 240 240 240 240 240
				240 240 240 240 240 240 240 240 240 240 240 240 240 240 240 240 240 240 240 240 240 240 240 240 240 240 240 240 240 240 240 240
				240 240 240 240 240 240 240 240 240 240 240 240 240 240 240 240 240 240 240 240 240 240 240 240 240 240 240 240 240 240 240 240
				240 240 240 240 240 240 240 240 240 240 240 240 240 240 240 240 240 240 240 240 240 240 240 240 240 240 240 240 240 240 240 240
				240 240 240 240 240 240 240 240 240 240 240 240 240 240 240 240 240 240 240 240 240 240 240 240 240 240 240 240 240 240 240 240
				240 240 240 240 240 240 240 240 240 240 240 240 240 240 240 240 240 240 240 240 240 240 240 240 240 240 240 240 240 240 240 240
				240 240 240 240 240 240 240 240 240 240 240 240 240 240 240 240 240 240 240 240 240 240 240 240 240 240 240 240 240 240 240 240
				240 240 240>;

			PS_Config_Lmt_LPWG_Diff_P = <
				75 75 75 75 75 75 75 75 75 75 75 75 75 75 75 75 75 75 75 75 75 75 75 75 75 75 75 75 75 75 75 75
				75 75 75 75 75 75 75 75 75 75 75 75 75 75 75 75 75 75 75 75 75 75 75 75 75 75 75 75 75 75 75 75
				75 75 75 75 75 75 75 75 75 75 75 75 75 75 75 75 75 75 75 75 75 75 75 75 75 75 75 75 75 75 75 75
				75 75 75 75 75 75 75 75 75 75 75 75 75 75 75 75 75 75 75 75 75 75 75 75 75 75 75 75 75 75 75 75
				75 75 75 75 75 75 75 75 75 75 75 75 75 75 75 75 75 75 75 75 75 75 75 75 75 75 75 75 75 75 75 75
				75 75 75 75 75 75 75 75 75 75 75 75 75 75 75 75 75 75 75 75 75 75 75 75 75 75 75 75 75 75 75 75
				75 75 75 75 75 75 75 75 75 75 75 75 75 75 75 75 75 75 75 75 75 75 75 75 75 75 75 75 75 75 75 75
				75 75 75 75 75 75 75 75 75 75 75 75 75 75 75 75 75 75 75 75 75 75 75 75 75 75 75 75 75 75 75 75
				75 75 75 75 75 75 75 75 75 75 75 75 75 75 75 75 75 75 75 75 75 75 75 75 75 75 75 75 75 75 75 75
				75 75 75 75 75 75 75 75 75 75 75 75 75 75 75 75 75 75 75 75 75 75 75 75 75 75 75 75 75 75 75 75
				75 75 75 75 75 75 75 75 75 75 75 75 75 75 75 75 75 75 75 75 75 75 75 75 75 75 75 75 75 75 75 75
				75 75 75 75 75 75 75 75 75 75 75 75 75 75 75 75 75 75 75 75 75 75 75 75 75 75 75 75 75 75 75 75
				75 75 75 75 75 75 75 75 75 75 75 75 75 75 75 75 75 75 75 75 75 75 75 75 75 75 75 75 75 75 75 75
				75 75 75 75 75 75 75 75 75 75 75 75 75 75 75 75 75 75 75 75 75 75 75 75 75 75 75 75 75 75 75 75
				75 75 75 75 75 75 75 75 75 75 75 75 75 75 75 75 75 75 75 75 75 75 75 75 75 75 75 75 75 75 75 75
				75 75 75 75 75 75 75 75 75 75 75 75 75 75 75 75 75 75 75 75 75 75 75 75 75 75 75 75 75 75 75 75
				75 75 75 75 75 75 75 75 75 75 75 75 75 75 75 75 75 75 75 75 75 75 75 75 75 75 75 75 75 75 75 75
				75 75 75 75 75 75 75 75 75 75 75 75 75 75 75 75 75 75 75 75 75 75 75 75 75 75 75 75 75 75 75 75
				75 75 75 75 75 75 75 75 75 75 75 75 75 75 75 75 75 75 75 75 75 75 75 75 75 75 75 75 75 75 75 75
				75 75 75 75 75 75 75 75 75 75 75 75 75 75 75 75 75 75 75 75 75 75 75 75 75 75 75 75 75 75 75 75
				75 75 75 75 75 75 75 75 75 75 75 75 75 75 75 75 75 75 75 75 75 75 75 75 75 75 75 75 75 75 75 75
				75 75 75 75 75 75 75 75 75 75 75 75 75 75 75 75 75 75 75 75 75 75 75 75 75 75 75 75 75 75 75 75
				75 75 75 75 75 75 75 75 75 75 75 75 75 75 75 75 75 75 75 75 75 75 75 75 75 75 75 75 75 75 75 75
				75 75 75 75 75 75 75 75 75 75 75 75 75 75 75 75 75 75 75 75 75 75 75 75 75 75 75 75 75 75 75 75
				75 75 75 75 75 75 75 75 75 75 75 75 75 75 75 75 75 75 75 75 75 75 75 75 75 75 75 75 75 75 75 75
				75 75 75 75 75 75 75 75 75 75 75 75 75 75 75 75 75 75 75 75 75 75 75 75 75 75 75 75 75 75 75 75
				75 75 75 75 75 75 75 75 75 75 75 75 75 75 75 75 75 75 75 75 75 75 75 75 75 75 75 75 75 75 75 75
				75 75 75 75 75 75 75 75 75 75 75 75 75 75 75 75 75 75 75 75 75 75 75 75 75 75 75 75 75 75 75 75
				75 75 75 75 75 75 75 75 75 75 75 75 75 75 75 75 75 75 75 75 75 75 75 75 75 75 75 75 75 75 75 75
				75 75 75 75 75 75 75 75 75 75 75 75 75 75 75 75 75 75 75 75 75 75 75 75 75 75 75 75 75 75 75 75
				75 75 75 75 75 75 75 75 75 75 75 75 75 75 75 75 75 75 75 75 75 75 75 75 75 75 75 75 75 75 75 75
				75 75 75 75 75 75 75 75 75 75 75 75 75 75 75 75 75 75 75 75 75 75 75 75 75 75 75 75 75 75 75 75
				75 75 75 75 75 75 75 75 75 75 75 75 75 75 75 75 75 75 75 75 75 75 75 75 75 75 75 75 75 75 75 75
				75 75 75 75 75 75 75 75 75 75 75 75 75 75 75 75 75 75 75 75 75 75 75 75 75 75 75 75 75 75 75 75
				75 75 75 75 75 75 75 75 75 75 75 75 75 75 75 75 75 75 75 75 75 75 75 75 75 75 75 75 75 75 75 75
				75 75 75 75 75 75 75 75 75 75 75 75 75 75 75 75 75 75 75 75 75 75 75 75 75 75 75 75 75 75 75 75
				75 75 75 75 75 75 75 75 75 75 75 75 75 75 75 75 75 75 75 75 75 75 75 75 75 75 75 75 75 75 75 75
				75 75 75 75 75 75 75 75 75 75 75 75 75 75 75 75 75 75 75 75 75 75 75 75 75 75 75 75 75 75 75 75
				75 75 75 75 75 75 75 75 75 75 75 75 75 75 75 75 75 75 75 75 75 75 75 75 75 75 75 75 75 75 75 75
				75 75 75 75 75 75 75 75 75 75 75 75 75 75 75 75 75 75 75 75 75 75 75 75 75 75 75 75 75 75 75 75
				75 75 75 75 75 75 75 75 75 75 75 75 75 75 75 75 75 75 75 75 75 75 75 75 75 75 75 75 75 75 75 75
				75 75 75 75 75 75 75 75 75 75 75 75 75 75 75 75 75 75 75 75 75 75 75 75 75 75 75 75 75 75 75 75
				75 75 75 75 75 75 75 75 75 75 75 75 75 75 75 75 75 75 75 75 75 75 75 75 75 75 75 75 75 75 75 75
				75 75 75 75 75 75 75 75 75 75 75 75 75 75 75 75 75 75 75 75 75 75 75 75 75 75 75 75 75 75 75 75
				75 75 75 75 75 75 75 75 75 75 75 75 75 75 75 75 75 75 75 75 75 75 75 75 75 75 75 75 75 75 75 75
				75 75 75 75 75 75 75 75 75 75 75 75 75 75 75 75 75 75 75 75 75 75 75 75 75 75 75 75 75 75 75 75
				75 75 75 75 75 75 75 75 75 75 75 75 75 75 75 75 75 75 75 75 75 75 75 75 75 75 75 75 75 75 75 75
				75 75 75 75 75 75 75 75 75 75 75 75 75 75 75 75 75 75 75 75 75 75 75 75 75 75 75 75 75 75 75 75
				75 75 75 75 75 75 75 75 75 75 75 75 75 75 75 75 75 75 75 75 75 75 75 75 75 75 75 75 75 75 75 75
				75 75 75 75 75 75 75 75 75 75 75 75 75 75 75 75 75 75 75 75 75 75 75 75 75 75 75 75 75 75 75 75
				75 75 75>;

			PS_Config_Lmt_LPWG_Diff_N = <
				(-75) (-75) (-75) (-75) (-75) (-75) (-75) (-75) (-75) (-75) (-75) (-75) (-75) (-75) (-75) (-75) (-75) (-75) (-75) (-75) (-75) (-75) (-75) (-75) (-75) (-75) (-75) (-75) (-75) (-75) (-75) (-75) (-75) (-75) (-75) (-75)
				(-75) (-75) (-75) (-75) (-75) (-75) (-75) (-75) (-75) (-75) (-75) (-75) (-75) (-75) (-75) (-75) (-75) (-75) (-75) (-75) (-75) (-75) (-75) (-75) (-75) (-75) (-75) (-75) (-75) (-75) (-75) (-75) (-75) (-75) (-75) (-75)
				(-75) (-75) (-75) (-75) (-75) (-75) (-75) (-75) (-75) (-75) (-75) (-75) (-75) (-75) (-75) (-75) (-75) (-75) (-75) (-75) (-75) (-75) (-75) (-75) (-75) (-75) (-75) (-75) (-75) (-75) (-75) (-75) (-75) (-75) (-75) (-75)
				(-75) (-75) (-75) (-75) (-75) (-75) (-75) (-75) (-75) (-75) (-75) (-75) (-75) (-75) (-75) (-75) (-75) (-75) (-75) (-75) (-75) (-75) (-75) (-75) (-75) (-75) (-75) (-75) (-75) (-75) (-75) (-75) (-75) (-75) (-75) (-75)
				(-75) (-75) (-75) (-75) (-75) (-75) (-75) (-75) (-75) (-75) (-75) (-75) (-75) (-75) (-75) (-75) (-75) (-75) (-75) (-75) (-75) (-75) (-75) (-75) (-75) (-75) (-75) (-75) (-75) (-75) (-75) (-75) (-75) (-75) (-75) (-75)
				(-75) (-75) (-75) (-75) (-75) (-75) (-75) (-75) (-75) (-75) (-75) (-75) (-75) (-75) (-75) (-75) (-75) (-75) (-75) (-75) (-75) (-75) (-75) (-75) (-75) (-75) (-75) (-75) (-75) (-75) (-75) (-75) (-75) (-75) (-75) (-75)
				(-75) (-75) (-75) (-75) (-75) (-75) (-75) (-75) (-75) (-75) (-75) (-75) (-75) (-75) (-75) (-75) (-75) (-75) (-75) (-75) (-75) (-75) (-75) (-75) (-75) (-75) (-75) (-75) (-75) (-75) (-75) (-75) (-75) (-75) (-75) (-75)
				(-75) (-75) (-75) (-75) (-75) (-75) (-75) (-75) (-75) (-75) (-75) (-75) (-75) (-75) (-75) (-75) (-75) (-75) (-75) (-75) (-75) (-75) (-75) (-75) (-75) (-75) (-75) (-75) (-75) (-75) (-75) (-75) (-75) (-75) (-75) (-75)
				(-75) (-75) (-75) (-75) (-75) (-75) (-75) (-75) (-75) (-75) (-75) (-75) (-75) (-75) (-75) (-75) (-75) (-75) (-75) (-75) (-75) (-75) (-75) (-75) (-75) (-75) (-75) (-75) (-75) (-75) (-75) (-75) (-75) (-75) (-75) (-75)
				(-75) (-75) (-75) (-75) (-75) (-75) (-75) (-75) (-75) (-75) (-75) (-75) (-75) (-75) (-75) (-75) (-75) (-75) (-75) (-75) (-75) (-75) (-75) (-75) (-75) (-75) (-75) (-75) (-75) (-75) (-75) (-75) (-75) (-75) (-75) (-75)
				(-75) (-75) (-75) (-75) (-75) (-75) (-75) (-75) (-75) (-75) (-75) (-75) (-75) (-75) (-75) (-75) (-75) (-75) (-75) (-75) (-75) (-75) (-75) (-75) (-75) (-75) (-75) (-75) (-75) (-75) (-75) (-75) (-75) (-75) (-75) (-75)
				(-75) (-75) (-75) (-75) (-75) (-75) (-75) (-75) (-75) (-75) (-75) (-75) (-75) (-75) (-75) (-75) (-75) (-75) (-75) (-75) (-75) (-75) (-75) (-75) (-75) (-75) (-75) (-75) (-75) (-75) (-75) (-75) (-75) (-75) (-75) (-75)
				(-75) (-75) (-75) (-75) (-75) (-75) (-75) (-75) (-75) (-75) (-75) (-75) (-75) (-75) (-75) (-75) (-75) (-75) (-75) (-75) (-75) (-75) (-75) (-75) (-75) (-75) (-75) (-75) (-75) (-75) (-75) (-75) (-75) (-75) (-75) (-75)
				(-75) (-75) (-75) (-75) (-75) (-75) (-75) (-75) (-75) (-75) (-75) (-75) (-75) (-75) (-75) (-75) (-75) (-75) (-75) (-75) (-75) (-75) (-75) (-75) (-75) (-75) (-75) (-75) (-75) (-75) (-75) (-75) (-75) (-75) (-75) (-75)
				(-75) (-75) (-75) (-75) (-75) (-75) (-75) (-75) (-75) (-75) (-75) (-75) (-75) (-75) (-75) (-75) (-75) (-75) (-75) (-75) (-75) (-75) (-75) (-75) (-75) (-75) (-75) (-75) (-75) (-75) (-75) (-75) (-75) (-75) (-75) (-75)
				(-75) (-75) (-75) (-75) (-75) (-75) (-75) (-75) (-75) (-75) (-75) (-75) (-75) (-75) (-75) (-75) (-75) (-75) (-75) (-75) (-75) (-75) (-75) (-75) (-75) (-75) (-75) (-75) (-75) (-75) (-75) (-75) (-75) (-75) (-75) (-75)
				(-75) (-75) (-75) (-75) (-75) (-75) (-75) (-75) (-75) (-75) (-75) (-75) (-75) (-75) (-75) (-75) (-75) (-75) (-75) (-75) (-75) (-75) (-75) (-75) (-75) (-75) (-75) (-75) (-75) (-75) (-75) (-75) (-75) (-75) (-75) (-75)
				(-75) (-75) (-75) (-75) (-75) (-75) (-75) (-75) (-75) (-75) (-75) (-75) (-75) (-75) (-75) (-75) (-75) (-75) (-75) (-75) (-75) (-75) (-75) (-75) (-75) (-75) (-75) (-75) (-75) (-75) (-75) (-75) (-75) (-75) (-75) (-75)
				(-75) (-75) (-75) (-75) (-75) (-75) (-75) (-75) (-75) (-75) (-75) (-75) (-75) (-75) (-75) (-75) (-75) (-75) (-75) (-75) (-75) (-75) (-75) (-75) (-75) (-75) (-75) (-75) (-75) (-75) (-75) (-75) (-75) (-75) (-75) (-75)
				(-75) (-75) (-75) (-75) (-75) (-75) (-75) (-75) (-75) (-75) (-75) (-75) (-75) (-75) (-75) (-75) (-75) (-75) (-75) (-75) (-75) (-75) (-75) (-75) (-75) (-75) (-75) (-75) (-75) (-75) (-75) (-75) (-75) (-75) (-75) (-75)
				(-75) (-75) (-75) (-75) (-75) (-75) (-75) (-75) (-75) (-75) (-75) (-75) (-75) (-75) (-75) (-75) (-75) (-75) (-75) (-75) (-75) (-75) (-75) (-75) (-75) (-75) (-75) (-75) (-75) (-75) (-75) (-75) (-75) (-75) (-75) (-75)
				(-75) (-75) (-75) (-75) (-75) (-75) (-75) (-75) (-75) (-75) (-75) (-75) (-75) (-75) (-75) (-75) (-75) (-75) (-75) (-75) (-75) (-75) (-75) (-75) (-75) (-75) (-75) (-75) (-75) (-75) (-75) (-75) (-75) (-75) (-75) (-75)
				(-75) (-75) (-75) (-75) (-75) (-75) (-75) (-75) (-75) (-75) (-75) (-75) (-75) (-75) (-75) (-75) (-75) (-75) (-75) (-75) (-75) (-75) (-75) (-75) (-75) (-75) (-75) (-75) (-75) (-75) (-75) (-75) (-75) (-75) (-75) (-75)
				(-75) (-75) (-75) (-75) (-75) (-75) (-75) (-75) (-75) (-75) (-75) (-75) (-75) (-75) (-75) (-75) (-75) (-75) (-75) (-75) (-75) (-75) (-75) (-75) (-75) (-75) (-75) (-75) (-75) (-75) (-75) (-75) (-75) (-75) (-75) (-75)
				(-75) (-75) (-75) (-75) (-75) (-75) (-75) (-75) (-75) (-75) (-75) (-75) (-75) (-75) (-75) (-75) (-75) (-75) (-75) (-75) (-75) (-75) (-75) (-75) (-75) (-75) (-75) (-75) (-75) (-75) (-75) (-75) (-75) (-75) (-75) (-75)
				(-75) (-75) (-75) (-75) (-75) (-75) (-75) (-75) (-75) (-75) (-75) (-75) (-75) (-75) (-75) (-75) (-75) (-75) (-75) (-75) (-75) (-75) (-75) (-75) (-75) (-75) (-75) (-75) (-75) (-75) (-75) (-75) (-75) (-75) (-75) (-75)
				(-75) (-75) (-75) (-75) (-75) (-75) (-75) (-75) (-75) (-75) (-75) (-75) (-75) (-75) (-75) (-75) (-75) (-75) (-75) (-75) (-75) (-75) (-75) (-75) (-75) (-75) (-75) (-75) (-75) (-75) (-75) (-75) (-75) (-75) (-75) (-75)
				(-75) (-75) (-75) (-75) (-75) (-75) (-75) (-75) (-75) (-75) (-75) (-75) (-75) (-75) (-75) (-75) (-75) (-75) (-75) (-75) (-75) (-75) (-75) (-75) (-75) (-75) (-75) (-75) (-75) (-75) (-75) (-75) (-75) (-75) (-75) (-75)
				(-75) (-75) (-75) (-75) (-75) (-75) (-75) (-75) (-75) (-75) (-75) (-75) (-75) (-75) (-75) (-75) (-75) (-75) (-75) (-75) (-75) (-75) (-75) (-75) (-75) (-75) (-75) (-75) (-75) (-75) (-75) (-75) (-75) (-75) (-75) (-75)
				(-75) (-75) (-75) (-75) (-75) (-75) (-75) (-75) (-75) (-75) (-75) (-75) (-75) (-75) (-75) (-75) (-75) (-75) (-75) (-75) (-75) (-75) (-75) (-75) (-75) (-75) (-75) (-75) (-75) (-75) (-75) (-75) (-75) (-75) (-75) (-75)
				(-75) (-75) (-75) (-75) (-75) (-75) (-75) (-75) (-75) (-75) (-75) (-75) (-75) (-75) (-75) (-75) (-75) (-75) (-75) (-75) (-75) (-75) (-75) (-75) (-75) (-75) (-75) (-75) (-75) (-75) (-75) (-75) (-75) (-75) (-75) (-75)
				(-75) (-75) (-75) (-75) (-75) (-75) (-75) (-75) (-75) (-75) (-75) (-75) (-75) (-75) (-75) (-75) (-75) (-75) (-75) (-75) (-75) (-75) (-75) (-75) (-75) (-75) (-75) (-75) (-75) (-75) (-75) (-75) (-75) (-75) (-75) (-75)
				(-75) (-75) (-75) (-75) (-75) (-75) (-75) (-75) (-75) (-75) (-75) (-75) (-75) (-75) (-75) (-75) (-75) (-75) (-75) (-75) (-75) (-75) (-75) (-75) (-75) (-75) (-75) (-75) (-75) (-75) (-75) (-75) (-75) (-75) (-75) (-75)
				(-75) (-75) (-75) (-75) (-75) (-75) (-75) (-75) (-75) (-75) (-75) (-75) (-75) (-75) (-75) (-75) (-75) (-75) (-75) (-75) (-75) (-75) (-75) (-75) (-75) (-75) (-75) (-75) (-75) (-75) (-75) (-75) (-75) (-75) (-75) (-75)
				(-75) (-75) (-75) (-75) (-75) (-75) (-75) (-75) (-75) (-75) (-75) (-75) (-75) (-75) (-75) (-75) (-75) (-75) (-75) (-75) (-75) (-75) (-75) (-75) (-75) (-75) (-75) (-75) (-75) (-75) (-75) (-75) (-75) (-75) (-75) (-75)
				(-75) (-75) (-75) (-75) (-75) (-75) (-75) (-75) (-75) (-75) (-75) (-75) (-75) (-75) (-75) (-75) (-75) (-75) (-75) (-75) (-75) (-75) (-75) (-75) (-75) (-75) (-75) (-75) (-75) (-75) (-75) (-75) (-75) (-75) (-75) (-75)
				(-75) (-75) (-75) (-75) (-75) (-75) (-75) (-75) (-75) (-75) (-75) (-75) (-75) (-75) (-75) (-75) (-75) (-75) (-75) (-75) (-75) (-75) (-75) (-75) (-75) (-75) (-75) (-75) (-75) (-75) (-75) (-75) (-75) (-75) (-75) (-75)
				(-75) (-75) (-75) (-75) (-75) (-75) (-75) (-75) (-75) (-75) (-75) (-75) (-75) (-75) (-75) (-75) (-75) (-75) (-75) (-75) (-75) (-75) (-75) (-75) (-75) (-75) (-75) (-75) (-75) (-75) (-75) (-75) (-75) (-75) (-75) (-75)
				(-75) (-75) (-75) (-75) (-75) (-75) (-75) (-75) (-75) (-75) (-75) (-75) (-75) (-75) (-75) (-75) (-75) (-75) (-75) (-75) (-75) (-75) (-75) (-75) (-75) (-75) (-75) (-75) (-75) (-75) (-75) (-75) (-75) (-75) (-75) (-75)
				(-75) (-75) (-75) (-75) (-75) (-75) (-75) (-75) (-75) (-75) (-75) (-75) (-75) (-75) (-75) (-75) (-75) (-75) (-75) (-75) (-75) (-75) (-75) (-75) (-75) (-75) (-75) (-75) (-75) (-75) (-75) (-75) (-75) (-75) (-75) (-75)
				(-75) (-75) (-75) (-75) (-75) (-75) (-75) (-75) (-75) (-75) (-75) (-75) (-75) (-75) (-75) (-75) (-75) (-75) (-75) (-75) (-75) (-75) (-75) (-75) (-75) (-75) (-75) (-75) (-75) (-75) (-75) (-75) (-75) (-75) (-75) (-75)
				(-75) (-75) (-75) (-75) (-75) (-75) (-75) (-75) (-75) (-75) (-75) (-75) (-75) (-75) (-75) (-75) (-75) (-75) (-75) (-75) (-75) (-75) (-75) (-75) (-75) (-75) (-75) (-75) (-75) (-75) (-75) (-75) (-75) (-75) (-75) (-75)
				(-75) (-75) (-75) (-75) (-75) (-75) (-75) (-75) (-75) (-75) (-75) (-75) (-75) (-75) (-75) (-75) (-75) (-75) (-75) (-75) (-75) (-75) (-75) (-75) (-75) (-75) (-75) (-75) (-75) (-75) (-75) (-75) (-75) (-75) (-75) (-75)
				(-75) (-75) (-75) (-75) (-75) (-75) (-75) (-75) (-75) (-75) (-75) (-75) (-75) (-75) (-75) (-75) (-75) (-75) (-75) (-75) (-75) (-75) (-75) (-75) (-75) (-75) (-75) (-75) (-75) (-75) (-75) (-75) (-75) (-75) (-75) (-75)
				(-75) (-75) (-75) (-75) (-75) (-75) (-75) (-75) (-75) (-75) (-75) (-75) (-75) (-75) (-75) (-75) (-75) (-75) (-75) (-75) (-75) (-75) (-75) (-75) (-75) (-75) (-75) (-75) (-75) (-75) (-75) (-75) (-75) (-75) (-75) (-75)
				(-75) (-75) (-75) (-75) (-75) (-75) (-75) (-75) (-75) (-75) (-75) (-75) (-75) (-75) (-75) (-75) (-75) (-75) (-75) (-75) (-75) (-75) (-75) (-75) (-75) (-75) (-75) (-75) (-75) (-75) (-75) (-75) (-75) (-75) (-75) (-75)
				(-75) (-75) (-75) (-75) (-75) (-75) (-75) (-75) (-75) (-75) (-75) (-75) (-75) (-75) (-75) (-75) (-75) (-75) (-75) (-75) (-75) (-75) (-75) (-75) (-75) (-75) (-75) (-75) (-75) (-75) (-75) (-75) (-75) (-75) (-75) (-75)
				(-75) (-75) (-75) (-75) (-75) (-75) (-75) (-75) (-75) (-75) (-75) (-75) (-75) (-75) (-75) (-75) (-75) (-75) (-75) (-75) (-75) (-75) (-75) (-75) (-75) (-75) (-75) (-75) (-75) (-75) (-75) (-75) (-75) (-75) (-75) (-75)
				(-75) (-75) (-75) (-75) (-75) (-75) (-75) (-75) (-75) (-75) (-75) (-75) (-75) (-75) (-75) (-75) (-75) (-75) (-75) (-75) (-75) (-75) (-75) (-75) (-75) (-75) (-75) (-75) (-75) (-75) (-75) (-75) (-75) (-75) (-75) (-75)
				(-75) (-75) (-75) (-75) (-75) (-75) (-75) (-75) (-75) (-75) (-75) (-75) (-75) (-75) (-75) (-75) (-75) (-75) (-75) (-75) (-75) (-75) (-75) (-75) (-75) (-75) (-75) (-75) (-75) (-75) (-75) (-75) (-75) (-75) (-75) (-75)
				(-75) (-75) (-75)>;

			/* FDM config */
			FDM_X_Channel = <2>;

			PS_Config_Lmt_FDM_Rawdata_P = <
				900 900
				900 900
				900 900
				900 900
				900 900
				900 900
				900 900
				900 900
				900 900
				900 900
				900 900
				900 900
				900 900
				900 900
				900 900
				900 900
				900 900
				900 900
				900 900
				900 900
				900 900
				900 900
				900 900
				900 900
				900 900
				900 900
				900 900
				900 900
				900 900
				900 900
				900 900
				900 900
				900 900
				900 900
				900 900
				900 900
				900 900
				900 900
				900 900
				900 900
				900 900
				900 900
				900 900
				900 900
				900 900
				900 900
				900 900
				900 900
				900 900
				900 900>;

			PS_Config_Lmt_FDM_Rawdata_N = <
				50 50
				50 50
				50 50
				50 50
				50 50
				50 50
				50 50
				50 50
				50 50
				50 50
				50 50
				50 50
				50 50
				50 50
				50 50
				50 50
				50 50
				50 50
				50 50
				50 50
				50 50
				50 50
				50 50
				50 50
				50 50
				50 50
				50 50
				50 50
				50 50
				50 50
				50 50
				50 50
				50 50
				50 50
				50 50
				50 50
				50 50
				50 50
				50 50
				50 50
				50 50
				50 50
				50 50
				50 50
				50 50
				50 50
				50 50
				50 50
				50 50
				50 50>;

			PS_Config_FDM_Noise_Test_Frame = <50>;
			PS_Config_Lmt_FDM_Diff_P = <
				180 180
				180 180
				180 180
				180 180
				180 180
				180 180
				180 180
				180 180
				180 180
				180 180
				180 180
				180 180
				180 180
				180 180
				180 180
				180 180
				180 180
				180 180
				180 180
				180 180
				180 180
				180 180
				180 180
				180 180
				180 180
				180 180
				180 180
				180 180
				180 180
				180 180
				180 180
				180 180
				180 180
				180 180
				180 180
				180 180
				180 180
				180 180
				180 180
				180 180
				180 180
				180 180
				180 180
				180 180
				180 180
				180 180
				180 180
				180 180
				180 180
				180 180>;

			PS_Config_Lmt_FDM_Diff_N = <
				(-180) (-180)
				(-180) (-180)
				(-180) (-180)
				(-180) (-180)
				(-180) (-180)
				(-180) (-180)
				(-180) (-180)
				(-180) (-180)
				(-180) (-180)
				(-180) (-180)
				(-180) (-180)
				(-180) (-180)
				(-180) (-180)
				(-180) (-180)
				(-180) (-180)
				(-180) (-180)
				(-180) (-180)
				(-180) (-180)
				(-180) (-180)
				(-180) (-180)
				(-180) (-180)
				(-180) (-180)
				(-180) (-180)
				(-180) (-180)
				(-180) (-180)
				(-180) (-180)
				(-180) (-180)
				(-180) (-180)
				(-180) (-180)
				(-180) (-180)
				(-180) (-180)
				(-180) (-180)
				(-180) (-180)
				(-180) (-180)
				(-180) (-180)
				(-180) (-180)
				(-180) (-180)
				(-180) (-180)
				(-180) (-180)
				(-180) (-180)
				(-180) (-180)
				(-180) (-180)
				(-180) (-180)
				(-180) (-180)
				(-180) (-180)
				(-180) (-180)
				(-180) (-180)
				(-180) (-180)
				(-180) (-180)
				(-180) (-180)>;
		};
	};

	/*Tab A8 code for SR-AX6300-01-448 by yuli at 2021/11/19 start*/
	focaltech@2 {
		compatible = "focaltech,fts-ot10";
		reg = <2>;
		status = "okay";
		spi-max-frequency = <6000000>;
		interrupt-parent = <&ap_gpio>;
		focaltech,reset-gpio = <&ap_gpio 145 0x01>;
		focaltech,irq-gpio = <&eic_async 0 0x02>;
		focaltech,max-touch-number = <10>;
		focaltech,display-coords =  <0 0 1199 1919>;
	};
	/*Tab A8 code for SR-AX6300-01-448 by yuli at 2021/11/19 end*/

};
/*Tab A8 code for SR-AX6300-01-373 by luxinjun at 2021/09/17 end*/
/*Tab A8 code for SR-AX6300-01-23 by fengzhigang at 2021/08/04 end*/
